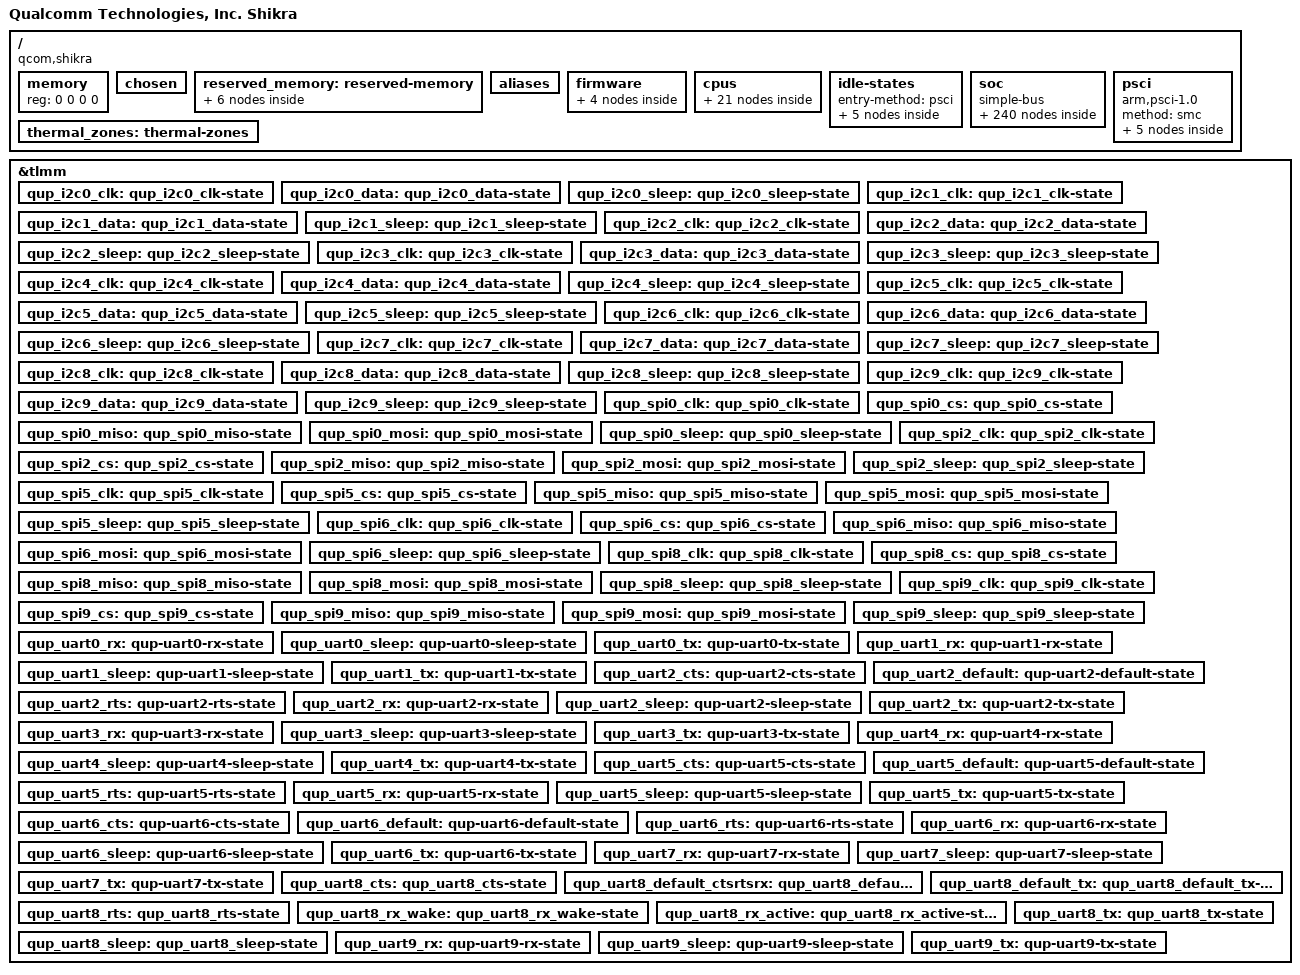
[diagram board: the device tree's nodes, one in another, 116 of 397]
// SPDX-License-Identifier: BSD-3-Clause
/*
 * Copyright (c) Qualcomm Technologies, Inc. and/or its subsidiaries.
 */

#include <dt-bindings/arm/msm/qti-smmu-proxy-dt-ids.h>
#include <dt-bindings/clock/qcom,rpmcc.h>
#include <dt-bindings/clock/qcom,shikra-audiocorecc.h>
#include <dt-bindings/clock/qcom,shikra-dispcc.h>
#include <dt-bindings/clock/qcom,shikra-gcc.h>
#include <dt-bindings/clock/qcom,shikra-gpucc.h>
#include <dt-bindings/dma/qcom-gpi.h>
#include <dt-bindings/interconnect/qcom,shikra.h>
#include <dt-bindings/interconnect/qcom,icc.h>
#include <dt-bindings/interrupt-controller/arm-gic.h>
#include <dt-bindings/regulator/qcom,rpm-smd-regulator.h>

/ {
	model = "Qualcomm Technologies, Inc. Shikra";
	compatible = "qcom,shikra";
	qcom,msm-id = <756 0x10000 >;
	interrupt-parent = <&intc>;
	#address-cells = <2>;
	#size-cells = <2>;
	memory { device_type = "memory"; reg = <0 0 0 0>; };

	chosen: chosen {
		bootargs = "android_arch_task_struct_size=512 pcie_ports=compat kasan=off irqaffinity=0-1 cpufreq.default_governor=performance printk.console_no_auto_verbose=1 rcupdate.rcu_expedited=1 rcu_nocbs=0-4 cgroup_disable=pressure cgroup.memory=nokmem,nosocket page_poison=on restrict_cma_redirect=false nokaslr kpti=0 log_buf_len=256K swiotlb=0 loop.max_part=7 loglevel=8 bootconfig sysctl.kernel.sched_pelt_multiplier=4 no-steal-acc fw_devlink.strict=1";

	};

	reserved_memory: reserved-memory { };

	aliases: aliases {
		serial0 = &uart0;
		mmc0 = &sdhc_1;
		mmc1 = &sdhc_2; /* SDC2 SD card slot */
		i2c3 = &i2c3;
		hsuart0 = &uart8;
	};

	firmware: firmware {
		qcom_scm: qcom_scm { };
	};

	cpus {
		#address-cells = <2>;
		#size-cells = <0>;

		CPU0: cpu@0 {
			device_type = "cpu";
			compatible = "qcom,kryo";
			reg = <0x0 0x0>;
			enable-method = "psci";
			cpu-idle-states = <&SILVER_OFF &SILVER_RAIL_OFF>;
			power-domains = <&CPU_PD0>;
			power-domain-names = "psci";
			d-cache-size = <0x8000>;
			i-cache-size = <0x8000>;
			next-level-cache = <&L3_0>;
			qcom,freq-domain = <&cpufreq_hw 0>;
			capacity-dmips-mhz = <1024>;
			dynamic-power-coefficient = <100>;
			#cooling-cells = <2>;

			L1_I_0: l1-icache {
				compatible = "cache";
			};

			L1_D_0: l1-dcache {
				compatible = "cache";
			};

			L3_0: l3-cache {
				compatible = "cache";
				cache-level = <3>;
				cache-size = <0x80000>;
			};
		};

		CPU1: cpu@100 {
			device_type = "cpu";
			compatible = "qcom,kryo";
			reg = <0x0 0x100>;
			enable-method = "psci";
			cpu-idle-states = <&SILVER_OFF &SILVER_RAIL_OFF>;
			power-domains = <&CPU_PD1>;
			power-domain-names = "psci";
			d-cache-size = <0x8000>;
			i-cache-size = <0x8000>;
			next-level-cache = <&L3_0>;
			qcom,freq-domain = <&cpufreq_hw 0>;
			capacity-dmips-mhz = <1024>;
			dynamic-power-coefficient = <100>;
			#cooling-cells = <2>;

			L1_I_1: l1-icache {
				compatible = "cache";
			};

			L1_D_1: l1-dcache {
				compatible = "cache";
			};
		};

		CPU2: cpu@200 {
			device_type = "cpu";
			compatible = "qcom,kryo";
			reg = <0x0 0x200>;
			enable-method = "psci";
			cpu-idle-states = <&SILVER_OFF &SILVER_RAIL_OFF>;
			power-domains = <&CPU_PD2>;
			power-domain-names = "psci";
			d-cache-size = <0x8000>;
			i-cache-size = <0x8000>;
			next-level-cache = <&L3_0>;
			qcom,freq-domain = <&cpufreq_hw 0>;
			capacity-dmips-mhz = <1024>;
			dynamic-power-coefficient = <100>;
			#cooling-cells = <2>;

			L1_I_2: l1-icache {
				compatible = "cache";
			};

			L1_D_2: l1-dcache {
				compatible = "cache";
			};
		};

		CPU3: cpu@300 {
			device_type = "cpu";
			compatible = "qcom,kryo";
			reg = <0x0 0x300>;
			enable-method = "psci";
			cpu-idle-states = <&GOLD_OFF &GOLD_RAIL_OFF>;
			power-domains = <&CPU_PD3>;
			power-domain-names = "psci";
			d-cache-size = <0x8000>;
			i-cache-size = <0x8000>;
			next-level-cache = <&L2_3>;
			qcom,freq-domain = <&cpufreq_hw 1>;
			capacity-dmips-mhz = <2273>;
			dynamic-power-coefficient = <494>;
			#cooling-cells = <2>;

			L1_I_3: l1-icache {
				compatible = "cache";
			};

			L1_D_3: l1-dcache {
				compatible = "cache";
			};

			L2_3: l2-cache {
				compatible = "cache";
				cache-level = <2>;
				cache-size = <0x40000>;
				next-level-cache = <&L3_0>;
			};
		};

		cpu-map {
			cluster0 {
				core0 {
					cpu = <&CPU0>;
				};

				core1 {
					cpu = <&CPU1>;
				};

				core2 {
					cpu = <&CPU2>;
				};
			};

			cluster1 {
				core0 {
					cpu = <&CPU3>;
				};
			};
		};
	};

	idle-states {
		entry-method = "psci";

		SILVER_OFF: silver-c3 {  /* C3 */
			compatible = "arm,idle-state";
			idle-state-name = "pc";
			entry-latency-us = <549>;
			exit-latency-us = <901>;
			min-residency-us = <1774>;
			arm,psci-suspend-param = <0x40000003>;
			local-timer-stop;
		};

		SILVER_RAIL_OFF: silver-cluster0-c4 { /* C4 */
			compatible = "arm,idle-state";
			idle-state-name = "rail-pc";
			entry-latency-us = <702>;
			exit-latency-us = <915>;
			min-residency-us = <4001>;
			arm,psci-suspend-param = <0x40000004>;
			local-timer-stop;
		};

		GOLD_OFF: gold-c3 {  /* C3 */
			compatible = "arm,idle-state";
			idle-state-name = "pc";
			entry-latency-us = <523>;
			exit-latency-us = <1244>;
			min-residency-us = <2207>;
			arm,psci-suspend-param = <0x40000003>;
			local-timer-stop;
		};

		GOLD_RAIL_OFF: gold-cluster1-c4 { /* C4 */
			compatible = "arm,idle-state";
			idle-state-name = "rail-pc";
			entry-latency-us = <526>;
			exit-latency-us = <1854>;
			min-residency-us = <5555>;
			arm,psci-suspend-param = <0x40000004>;
			local-timer-stop;
		};

		CLUSTER_PWR_DN: cluster-d4 { /* D4 */
			compatible = "domain-idle-state";
			idle-state-name = "l3-pc";
			entry-latency-us = <2752>;
			exit-latency-us = <3038>;
			min-residency-us = <6118>;
			arm,psci-suspend-param = <0x41000044>;
		};
	};

	soc: soc { };

	thermal_zones: thermal-zones {};

	psci {
		compatible = "arm,psci-1.0";
		method = "smc";

		CPU_PD0: cpu-pd0 {
			#power-domain-cells = <0>;
			power-domains = <&CLUSTER_PD>;
		};

		CPU_PD1: cpu-pd1 {
			#power-domain-cells = <0>;
			power-domains = <&CLUSTER_PD>;
		};

		CPU_PD2: cpu-pd2 {
			#power-domain-cells = <0>;
			power-domains = <&CLUSTER_PD>;
		};

		CPU_PD3: cpu-pd3 {
			#power-domain-cells = <0>;
			power-domains = <&CLUSTER_PD>;
		};

		CLUSTER_PD: cluster-pd {
			#power-domain-cells = <0>;
			domain-idle-states = <&CLUSTER_PWR_DN>;
		};
	};
};

&firmware {
	qcom_scm {
		compatible = "qcom,scm";
		qcom,dload-mode = <&tcsr 0x13000>;
	};

	qcom_smcinvoke {
		compatible = "qcom,smcinvoke";
	};

	qcom_mem_object {
		compatible = "qcom,mem-object";
	};

	qtee_shmbridge {
		compatible = "qcom,tee-shared-memory-bridge";
	};
};

&soc {
	#address-cells = <1>;
	#size-cells = <1>;
	ranges = <0 0 0 0xffffffff>;
	compatible = "simple-bus";

	rpm_bus: qcom,rpm-smd {
		compatible = "qcom,rpm-smd";
		rpm-channel-name = "rpm_requests";
		interrupts = <GIC_SPI 194 IRQ_TYPE_EDGE_RISING>;
		rpm-channel-type = <15>; /* SMD_APPS_RPM */
		power-domains = <&CLUSTER_PD>;
	};

	cluster-device {
		compatible = "qcom,lpm-cluster-dev";
		power-domains = <&CLUSTER_PD>;
	};

	mpm: interrupt-controller@45f01b8 {
		compatible = "qcom,mpm-shikra", "qcom,mpm";
		reg = <0x045f01b8 0x1000>,
		      <0x0f40000c 0x4>,  /* MSM_APCS_GCC_BASE 4K */
		      <0x0f421000 0x1000>;
		reg-names = "vmpm", "ipc", "timer";
		interrupts = <GIC_SPI 197 IRQ_TYPE_EDGE_RISING>;
		qcom,num-mpm-irqs = <96>;
		interrupt-controller;
		interrupt-parent = <&intc>;
		#interrupt-cells = <2>;
	};

	msm_gpu: qcom,kgsl-3d0@5900000 { };

	intc: interrupt-controller@f200000 {
		compatible = "arm,gic-v3";
		#interrupt-cells = <3>;
		interrupt-controller;
		#redistributor-regions = <1>;
		redistributor-stride = <0x0 0x20000>;
		reg = <0xf200000 0x10000>,	/* GICD */
		      <0xf240000 0x80000>;	/* GICR * 4 */
		interrupts = <GIC_PPI 8 IRQ_TYPE_LEVEL_HIGH>;
	};

	qcom_tzlog: tz-log@c11e720 {
		compatible = "qcom,tz-log";
		reg = <0xc11e720 0x3000>;
		qcom,hyplog-enabled;
		hyplog-address-offset = <0x410>;
		hyplog-size-offset = <0x414>;
	};

	arch_timer: timer {
		compatible = "arm,armv8-timer";
		interrupts = <GIC_PPI 1 (GIC_CPU_MASK_SIMPLE(8) | IRQ_TYPE_LEVEL_LOW)>,
			     <GIC_PPI 2 (GIC_CPU_MASK_SIMPLE(8) | IRQ_TYPE_LEVEL_LOW)>,
			     <GIC_PPI 3 (GIC_CPU_MASK_SIMPLE(8) | IRQ_TYPE_LEVEL_LOW)>,
			     <GIC_PPI 0 (GIC_CPU_MASK_SIMPLE(8) | IRQ_TYPE_LEVEL_LOW)>;
		clock-frequency = <19200000>;
	};
	ethernet: ethernet@5d00000 {
		compatible = "qcom,shikra-ethqos";
		reg = <0x05d00000 0x10000>,
		      <0x05d16000 0x100>;
		reg-names = "stmmaceth", "rgmii";

		clocks = <&gcc GCC_EMAC0_AXI_CLK>,
			 <&gcc GCC_EMAC0_AHB_CLK>,
			 <&gcc GCC_EMAC0_PTP_CLK>,
			 <&gcc GCC_EMAC0_RGMII_CLK>,
			 <&gcc GCC_EMAC0_AXI_CLK>,
			 <&gcc GCC_EMAC0_AXI_SYS_NOC_CLK>,
			 <&gcc GCC_PCIE_TILE_AXI_SYS_NOC_CLK>;
		clock-names = "stmmaceth", "pclk", "ptp_ref", "rgmii",
			      "axi", "axi-noc", "pcie-tile-axi-noc";

		interrupts = <GIC_SPI 478 IRQ_TYPE_LEVEL_HIGH>,
			     <GIC_SPI 469 IRQ_TYPE_LEVEL_HIGH>;
		interrupt-names = "macirq", "eth_lpi";

		power-domains = <&gcc GCC_EMAC0_GDSC>;
		resets = <&gcc GCC_EMAC0_BCR>;
		reset-names = "stmmaceth";
		iommus = <&apps_smmu 0x380 0x7>;
		qcom,iommu-dma = "atomic";

		interconnect-names = "axi_icc_path", "apb_icc_path";
		interconnects = <&system_noc MASTER_EMAC_0 &mc_virt SLAVE_EBI_CH0>,
				<&mem_noc MASTER_AMPSS_M0 &config_noc SLAVE_EMAC0_CFG>;

		snps,tso;
		snps,pbl = <32>;
		rx-fifo-depth = <8192>;
		tx-fifo-depth = <8192>;

		status = "disabled";
	};

	memtimer: timer@f420000 {
		#address-cells = <1>;
		#size-cells = <1>;
		ranges;
		compatible = "arm,armv7-timer-mem";
		reg = <0x0f420000 0x1000>;
		clock-frequency = <19200000>;

		frame@f421000 {
			frame-number = <0>;
			interrupts = <GIC_SPI 8 IRQ_TYPE_LEVEL_HIGH>,
				     <GIC_SPI 6 IRQ_TYPE_LEVEL_HIGH>;
			reg = <0x0f421000 0x1000>,
			      <0x0f422000 0x1000>;
		};

		frame@f423000 {
			frame-number = <1>;
			interrupts = <GIC_SPI 9 IRQ_TYPE_LEVEL_HIGH>;
			reg = <0xf243000 0x1000>;
			status = "disabled";
		};

		frame@f425000 {
			frame-number = <2>;
			interrupts = <GIC_SPI 10 IRQ_TYPE_LEVEL_HIGH>;
			reg = <0xf425000 0x1000>;
			status = "disabled";
		};

		frame@f427000 {
			frame-number = <3>;
			interrupts = <GIC_SPI 11 IRQ_TYPE_LEVEL_HIGH>;
			reg = <0xf427000 0x1000>;
			status = "disabled";
		};

		frame@f429000 {
			frame-number = <4>;
			interrupts = <GIC_SPI 12 IRQ_TYPE_LEVEL_HIGH>;
			reg = <0xf429000 0x1000>;
			status = "disabled";
		};

		frame@f42b000 {
			frame-number = <5>;
			interrupts = <GIC_SPI 13 IRQ_TYPE_LEVEL_HIGH>;
			reg = <0xf42b000 0x1000>;
			status = "disabled";
		};

		frame@f42d000 {
			frame-number = <6>;
			interrupts = <GIC_SPI 14 IRQ_TYPE_LEVEL_HIGH>;
			reg = <0xf42d000 0x1000>;
			status = "disabled";
		};
	};

	wdog: qcom,wdt@f410000 {
		compatible = "qcom,msm-watchdog";
		reg = <0xf410000 0x1000>;
		reg-names = "wdt-base";
		interrupts = <GIC_SPI 0 IRQ_TYPE_LEVEL_HIGH>,
			     <GIC_SPI 1 IRQ_TYPE_LEVEL_HIGH>;
		qcom,bark-time = <11000>;
		qcom,pet-time = <9360>;
		qcom,ipi-ping;
		qcom,wakeup-enable;
		status = "ok";
	};

	gic-interrupt-router {
		compatible = "qcom,gic-intr-routing";
		/* keep a few m cores in class0 only to avoid wakeup of l cores */
		qcom,gic-class0-cpus = <&CPU0 &CPU1 &CPU2>;
		/* keep other cores in class1 */
		qcom,gic-class1-cpus = <&CPU3>;
	};

	qcom,mem-buf {
		compatible = "qcom,mem-buf";
		qcom,mem-buf-capabilities = "supplier";
		qcom,vmid = <3>;
	};

	qcom,mem-buf-msgq {
		compatible = "qcom,mem-buf-msgq";
		qcom,msgq-names = "trusted_vm", "oem_vm";
	};

	qcom,test-large-dmabuf-tuivm {
		compatible = "qcom,gh-large-dmabuf-test";
		gunyah-label = <0x10d>;
		qcom,primary;
	};

	kryo-erp {
		compatible = "arm,arm64-kryo-cpu-erp";
		interrupts = <GIC_PPI 6 IRQ_TYPE_LEVEL_HIGH>,
			     <GIC_SPI 35 IRQ_TYPE_LEVEL_HIGH>;
		interrupt-names = "l1-l2-faultirq","l3-scu-faultirq";
	};

	qcom,rmtfs_sharedmem@0 {
		compatible = "qcom,sharedmem-uio";
		reg = <0x0 0x400000>;
		reg-names = "rmtfs";
		qcom,client-id = <0x00000001>;
		qcom,guard-memory;
		qcom,vm-nav-path;
	};

	cpu_pmu: cpu-pmu {
		compatible = "arm,armv8-pmuv3";
		interrupts = <GIC_PPI 5 IRQ_TYPE_LEVEL_HIGH>;
	};

	clocks {
		xo_board: xo_board {
			compatible = "fixed-clock";
			clock-frequency = <38400000>;
			clock-output-names = "xo_board";
			#clock-cells = <0>;
		};

		sleep_clk: sleep_clk {
			compatible = "fixed-clock";
			clock-frequency = <32764>;
			clock-output-names = "sleep_clk";
			#clock-cells = <0>;
		};

		emac0_sgmiiphy_rclk: emac0_sgmiiphy_rclk {
			compatible = "fixed-clock";
			clock-frequency = <1000>;
			clock-output-names = "emac0_sgmiiphy_rclk";
			#clock-cells = <0>;
		};

		emac0_sgmiiphy_tclk: emac0_sgmiiphy_tclk {
			compatible = "fixed-clock";
			clock-frequency = <1000>;
			clock-output-names = "emac0_sgmiiphy_tclk";
			#clock-cells = <0>;
		};

		emac1_sgmiiphy_rclk: emac1_sgmiiphy_rclk {
			compatible = "fixed-clock";
			clock-frequency = <1000>;
			clock-output-names = "emac1_sgmiiphy_rclk";
			#clock-cells = <0>;
		};

		emac1_sgmiiphy_tclk: emac1_sgmiiphy_tclk {
			compatible = "fixed-clock";
			clock-frequency = <1000>;
			clock-output-names = "emac1_sgmiiphy_tclk";
			#clock-cells = <0>;
		};

		pcie_pipe_clk: pcie_pipe_clk {
			compatible = "fixed-clock";
			clock-frequency = <1000>;
			clock-output-names = "pcie_pipe_clk";
			#clock-cells = <0>;
		};

		usb3_phy_wrapper_gcc_usb30_pipe_clk: usb3_phy_wrapper_gcc_usb30_pipe_clk {
			compatible = "fixed-clock";
			clock-frequency = <1000>;
			clock-output-names = "usb3_phy_wrapper_gcc_usb30_pipe_clk";
			#clock-cells = <0>;
		};
	};

	rpmcc: clock-controller {
		compatible = "qcom,rpmcc-shikra";
		#clock-cells = <1>;
	};

	audiocorecc: clock-controller@a0a0000 {
		compatible = "qcom,shikra-audiocorecc";
		reg = <0xa0a0000 0x10000>;
		reg-name = "cc_base";
		vdd_cx-supply = <&VDD_CX_LEVEL>;
		clocks = <&rpmcc RPM_SMD_XO_CLK_SRC>,
			 <&gcc GCC_LPASS_CONFIG_CLK>,
			 <&gcc GCC_LPASS_CORE_AXIM_CLK>,
			 <&sleep_clk>;
		clock-names = "bi_tcxo",
			      "lpass_config_clk",
			      "lpass_core_axim_clk",
			      "sleep_clk";
		#clock-cells = <1>;
		#reset-cells = <1>;
		status = "disabled";
	};

	dispcc: clock-controller@5f00000 {
		compatible = "qcom,shikra-dispcc", "syscon";
		reg = <0x5f00000 0x20000>;
		reg-name = "cc_base";
		vdd_cx-supply = <&VDD_CX_LEVEL>;
		clocks = <&rpmcc RPM_SMD_XO_CLK_SRC>,
			 <&sleep_clk>,
			 <&gcc GCC_DISP_AHB_CLK>,
			 <&gcc GCC_DISP_GPLL0_DIV_CLK_SRC>;
		clock-names = "bi_tcxo",
			      "sleep_clk",
			      "iface",
			      "gcc_disp_gpll0_div_clk_src";
		#clock-cells = <1>;
		#reset-cells = <1>;
		#power-domain-cells = <1>;
	};

	gcc: clock-controller@1400000 {
		compatible = "qcom,shikra-gcc", "syscon";
		reg = <0x1400000 0x1f0000>;
		reg-name = "cc_base";
		vdd_cx-supply = <&VDD_CX_LEVEL>;
		vdd_mx-supply = <&VDD_MX_LEVEL>;
		clocks = <&rpmcc RPM_SMD_XO_CLK_SRC>,
			 <&emac0_sgmiiphy_rclk>,
			 <&emac0_sgmiiphy_tclk>,
			 <&emac1_sgmiiphy_rclk>,
			 <&emac1_sgmiiphy_tclk>,
			 <&pcie_pipe_clk>,
			 <&sleep_clk>,
			 <&usb3_phy_wrapper_gcc_usb30_pipe_clk>;
		clock-names = "bi_tcxo",
			      "emac0_sgmiiphy_rclk",
			      "emac0_sgmiiphy_tclk",
			      "emac1_sgmiiphy_rclk",
			      "emac1_sgmiiphy_tclk",
			      "pcie_pipe_clk",
			      "sleep_clk",
			      "usb3_phy_wrapper_gcc_usb30_pipe_clk";
		protected-clocks = <GCC_LPASS_CONFIG_CLK>,
				   <GCC_LPASS_CORE_AXIM_CLK>;
		#clock-cells = <1>;
		#reset-cells = <1>;
		#power-domain-cells = <1>;
	};

	gpucc: clock-controller@5990000 {
		compatible = "qcom,shikra-gpucc", "syscon";
		reg = <0x5990000 0x9000>;
		reg-name = "cc_base";
		vdd_cx-supply = <&VDD_CX_LEVEL>;
		clocks = <&rpmcc RPM_SMD_XO_CLK_SRC>,
			 <&gcc GCC_GPU_GPLL0_CLK_SRC>,
			 <&gcc GCC_GPU_GPLL0_DIV_CLK_SRC>;
		clock-names = "bi_tcxo",
			      "gpll0_out_main",
			      "gpll0_out_main_div";
		#clock-cells = <1>;
		#reset-cells = <1>;
		#power-domain-cells = <1>;
	};

	cpufreq_hw: qcom,cpufreq-hw {
		compatible = "qcom,cpufreq-rimps";
		reg = <0xfd91000 0x1000>,
		      <0xfd92000 0x1000>;
		reg-names = "freq-domain0",
			    "freq-domain1";
		clocks = <&rpmcc RPM_SMD_XO_CLK_SRC>, <&gcc GPLL0>;
		clock-names = "xo", "alternate";
		interrupts = <GIC_SPI 30 IRQ_TYPE_LEVEL_HIGH>,
			     <GIC_SPI 31 IRQ_TYPE_LEVEL_HIGH>;
		interrupt-names = "dcvsh0_int",
				  "dcvsh1_int";
		#freq-domain-cells = <1>;
	};

	qcom,cpufreq-hw-debug {
		compatible = "qcom,cpufreq-hw-epss-debug";
		qcom,freq-hw-domain = <&cpufreq_hw 0>,
				      <&cpufreq_hw 1>;
	};

	mccc_debug: syscon@cba000 {
		compatible = "syscon";
		reg = <0xcba000 0x54>;
	};

	cpucc_debug: syscon@faa0018 {
		compatible = "syscon";
		reg = <0xfaa0018 0x4>;
	};

	debugcc: clock-controller@0 {
		compatible = "qcom,shikra-debugcc";
		qcom,gcc = <&gcc>;
		qcom,dispcc = <&dispcc>;
		qcom,gpucc = <&gpucc>;
		qcom,mccc = <&mccc_debug>;
		qcom,cpucc = <&cpucc_debug>;
		clocks = <&rpmcc RPM_SMD_XO_CLK_SRC>,
			 <&gcc 0>,
			 <&dispcc 0>,
			 <&gpucc 0>;
		clock-names = "xo_clk_src",
			      "gcc",
			      "dispcc",
			      "gpucc";
		#clock-cells = <1>;
	};

	clk_virt: interconnect@0 {
		compatible = "qcom,shikra-clk_virt";
		#interconnect-cells = <1>;
		qcom,keepalive;
		clock-names = "bus", "bus_a";
		clocks = <&rpmcc RPM_SMD_QUP_CLK>,
			 <&rpmcc RPM_SMD_QUP_A_CLK>;
	};

	mc_virt: interconnect@1 {
		reg = <0x04480000 0x80000>;
		compatible = "qcom,shikra-mc_virt";
		#interconnect-cells = <1>;
		qcom,util-factor = <152>;
		qcom,keepalive;
		clock-names = "bus", "bus_a";
		clocks = <&rpmcc RPM_SMD_BIMC_CLK>,
			 <&rpmcc RPM_SMD_BIMC_A_CLK>;
	};

	mem_noc: interconnect@d00000 {
		reg = <0x00d00000 0x43080>;
		compatible = "qcom,shikra-mem_noc_core";
		#interconnect-cells = <1>;
		qcom,util-factor = <142>;
		qcom,keepalive;
		clock-names = "bus", "bus_a";
		clocks = <&rpmcc RPM_SMD_CPUSS_GNOC_CLK>,
			 <&rpmcc RPM_SMD_CPUSS_GNOC_A_CLK>,
			 <&gcc GCC_DDRSS_GPU_AXI_CLK>;
	};

	mmnrt_virt: interconnect1@1880000 {
		reg = <0x01880000 0x6a080>;
		compatible = "qcom,shikra-mmnrt_virt";
		#interconnect-cells = <1>;
		qcom,util-factor = <142>;
		qcom,keepalive;
		clock-names = "bus", "bus_a";
		clocks = <&rpmcc RPM_SMD_MMNRT_CLK>,
			 <&rpmcc RPM_SMD_MMNRT_A_CLK>;
	};

	mmrt_virt: interconnect2@1880000 {
		reg = <0x01880000 0x6a080>;
		compatible = "qcom,shikra-mmrt_virt";
		#interconnect-cells = <1>;
		qcom,util-factor = <142>;
		qcom,keepalive;
		clock-names = "bus", "bus_a";
		clocks = <&rpmcc RPM_SMD_MMRT_CLK>,
			 <&rpmcc RPM_SMD_MMRT_A_CLK>;
	};

	system_noc: interconnect@1880000 {
		reg = <0x01880000 0x6a080>;
		compatible = "qcom,shikra-sys_noc";
		#interconnect-cells = <1>;
		qcom,keepalive;
		clock-names = "bus", "bus_a";
		clocks = <&rpmcc RPM_SMD_SNOC_CLK>,
			 <&rpmcc RPM_SMD_SNOC_A_CLK>,
			 <&gcc GCC_EMAC0_AXI_SYS_NOC_CLK>,
			 <&gcc GCC_EMAC1_AXI_SYS_NOC_CLK>,
			 <&gcc GCC_SYS_NOC_USB2_PRIM_AXI_CLK>,
			 <&gcc GCC_SYS_NOC_USB3_PRIM_AXI_CLK>;
	};

	config_noc: interconnect@1900000 {
		reg = <0x01900000 0x8080>;
		compatible = "qcom,shikra-config_noc";
		#interconnect-cells = <1>;
		qcom,keepalive;
		clock-names = "bus", "bus_a";
		clocks = <&rpmcc RPM_SMD_CNOC_CLK>,
			 <&rpmcc RPM_SMD_CNOC_A_CLK>;
	};

	vendor_hooks: qcom,cpu-vendor-hooks {
		compatible = "qcom,cpu-vendor-hooks";
	};

	qcom,secure-buffer {
		compatible = "qcom,secure-buffer";
		qcom,vmid-cp-camera-preview-ro;
	};

	qti,smmu-proxy {
		compatible = "smmu-proxy-sender";
	};

	qcom,seccamtest {
		compatible = "qcom,seccamtest";
		qti,smmu-proxy-cb-id = <QTI_SMMU_PROXY_CAMERA_CB>;
	};

	logbuf: qcom,logbuf-vendor-hooks {
		compatible = "qcom,logbuf-vendor-hooks";
	};

	va_mini_dump {
		compatible = "qcom,va-minidump";
		memory-region = <&va_md_mem>;
		status = "ok";
	};

	google,debug-kinfo {
		compatible = "google,debug-kinfo";
		memory-region = <&kinfo_mem>;
	};

	mini_dump_mode {
		compatible = "qcom,minidump";
		status = "ok";
	};

	qcom,mpm2-sleep-counter@4403000 {
		compatible = "qcom,mpm2-sleep-counter";
		reg = <0x4403000 0x1000>;
		clock-frequency = <32768>;
	};

	tcsr_mutex_block: syscon@340000 {
		compatible = "syscon";
		reg = <0x340000 0x20000>;
	};

	tcsr_mutex: hwlock {
		compatible = "qcom,tcsr-mutex";
		syscon = <&tcsr_mutex_block 0 0x1000>;
		#hwlock-cells = <1>;
	};

	rpm_msg_ram: memory@45f0000 {
		compatible = "qcom,rpm-msg-ram";
		reg = <0x45f0000 0x7000>;
	};

	sram@4690000 {
		compatible = "qcom,rpm-stats-v2";
		reg = <0x04690000 0x10000>;
		ss-name = "modem", "cdsp", "apss", "lmcu";
	};

	apcs_glb: mailbox@f400000 {
		compatible = "qcom,shikra-apcs-hmss-global";
		reg = <0xf400000 0x1000>;
		#mbox-cells = <1>;
	};

	rpm-glink {
		compatible = "qcom,glink-rpm";
		interrupts = <GIC_SPI 194 IRQ_TYPE_EDGE_RISING>;
		qcom,rpm-msg-ram = <&rpm_msg_ram>;
		mboxes = <&apcs_glb 0>;
	};

	qcom,smp2p-modem {
		compatible = "qcom,smp2p";
		qcom,smem = <435>, <428>;
		interrupts = <GIC_SPI 70 IRQ_TYPE_EDGE_RISING>;
		mboxes = <&apcs_glb 14>;
		qcom,local-pid = <0>;
		qcom,remote-pid = <1>;

		modem_smp2p_out: master-kernel {
			qcom,entry-name = "master-kernel";
			#qcom,smem-state-cells = <1>;
		};

		modem_smp2p_in: slave-kernel {
			qcom,entry-name = "slave-kernel";
			interrupt-controller;
			#interrupt-cells = <2>;
		};

		smp2p_ipa_1_out: qcom,smp2p-ipa-1-out {
			qcom,entry-name = "ipa";
			#qcom,smem-state-cells = <1>;
		};

		/* ipa - inbound entry from mss */
		smp2p_ipa_1_in: qcom,smp2p-ipa-1-in {
			qcom,entry-name = "ipa";
			interrupt-controller;
			#interrupt-cells = <2>;
		};

		smp2p_wlan_1_in: qcom,smp2p-wlan-1-in {
			qcom,entry-name = "wlan";
			interrupt-controller;
			#interrupt-cells = <2>;
		};

	};

	qcom,smp2p-cdsp {
		compatible = "qcom,smp2p";
		qcom,smem = <94>, <432>;
		interrupts = <GIC_SPI 263 IRQ_TYPE_EDGE_RISING>;
		mboxes = <&apcs_glb 6>;
		qcom,local-pid = <0>;
		qcom,remote-pid = <5>;

		cdsp_smp2p_out: master-kernel {
			qcom,entry-name = "master-kernel";
			#qcom,smem-state-cells = <1>;
		};

		cdsp_smp2p_in: slave-kernel {
			qcom,entry-name = "slave-kernel";
			interrupt-controller;
			#interrupt-cells = <2>;
		};

		smp2p_rdbg5_out: qcom,smp2p-rdbg5-out {
			qcom,entry-name = "rdbg";
			#qcom,smem-state-cells = <1>;
		};

		smp2p_rdbg5_in: qcom,smp2p-rdbg5-in {
			qcom,entry-name = "rdbg";
			interrupt-controller;
			#interrupt-cells = <2>;
		};
	};

	qcom,smp2p-lmcu {
		compatible = "qcom,smp2p";
		qcom,smem = <617>, <616>;
		interrupts = <GIC_SPI 287 IRQ_TYPE_EDGE_RISING>;
		mboxes = <&apcs_glb 10>;
		qcom,local-pid = <0>;
		qcom,remote-pid = <26>;

		lmcu_smp2p_out: master-kernel {
			qcom,entry-name = "master-kernel";
			#qcom,smem-state-cells = <1>;
		};

		lmcu_smp2p_in: slave-kernel {
			qcom,entry-name = "slave-kernel";
			interrupt-controller;
			#interrupt-cells = <2>;
		};

		lmcu_sleepstate_smp2p_out: sleepstate-out {
			qcom,entry-name = "sleepstate";
			#qcom,smem-state-cells = <1>;
		};

		lmcu_sleepstate_smp2p_in: qcom,sleepstate-in {
			qcom,entry-name = "sleepstate_see";
			interrupt-controller;
			#interrupt-cells = <2>;
		};
	};

	qcom,smp2p_sleepstate_lmcu {
		compatible = "qcom,smp2p-sleepstate";
		qcom,smem-states = <&lmcu_sleepstate_smp2p_out 0>;
		interrupt-parent = <&lmcu_sleepstate_smp2p_in>;
		interrupts = <0 0>;
		label = "lmcu";
		interrupt-names = "smp2p-sleepstate-in";
	};

	apcs: syscon@f400000 {
		compatible = "syscon";
		reg = <0xf400000 0x1000>;
	};

	qcom,smsm {
		compatible = "qcom,smsm";

		#address-cells = <1>;
		#size-cells = <0>;

		qcom,ipc-1 = <&apcs 12 13>;

		apps_smsm_out: apps@0 {
			reg = <0>;
			#qcom,smem-state-cells = <1>;
		};

		modem_smsm_in: modem@1 {
			reg = <1>;
			interrupts = <GIC_SPI 69 IRQ_TYPE_EDGE_RISING>;

			interrupt-controller;
			#interrupt-cells = <2>;
		};
	};

	qcom,bam_dmux@6044000 {
		compatible = "qcom,bam_dmux";
		reg = <0x6044000 0x19000>;
		qcom,rx-ring-size = <32>;
		qcom,max-rx-mtu = <4096>;
		qcom,fast-shutdown;
		qcom,smem-states = <&apps_smsm_out 1>, <&apps_smsm_out 11>;
		qcom,smem-state-names = "pwrctrl", "pwrctrlack";
		interrupts-extended =
			<&intc GIC_SPI 74 IRQ_TYPE_EDGE_RISING>,
			<&modem_smsm_in 1 IRQ_TYPE_EDGE_BOTH>,
			<&modem_smsm_in 11 IRQ_TYPE_EDGE_BOTH>;
		interrupt-names = "dmux", "ctrl", "ack";
		};

	qup0_gpi_iommu_region: qup0_gpi_iommu_region {
		iommu-addresses = <&gpi_dma0 0x0 0x100000>,
				  <&gpi_dma0 0x200000 0xffe00000>;
	};

	gpi_dma0: qcom,gpi-dma@4a00000 {
		compatible = "qcom,gpi-dma";
		#dma-cells = <5>;
		reg = <0x4a00000 0x60000>;
		reg-names = "gpi-top";
		iommus = <&apps_smmu 0xf6 0x0>;
		qcom,max-num-gpii = <16>;
		interrupts = <GIC_SPI 511 IRQ_TYPE_LEVEL_HIGH>,
			     <GIC_SPI 512 IRQ_TYPE_LEVEL_HIGH>,
			     <GIC_SPI 513 IRQ_TYPE_LEVEL_HIGH>,
			     <GIC_SPI 514 IRQ_TYPE_LEVEL_HIGH>,
			     <GIC_SPI 515 IRQ_TYPE_LEVEL_HIGH>,
			     <GIC_SPI 516 IRQ_TYPE_LEVEL_HIGH>,
			     <GIC_SPI 517 IRQ_TYPE_LEVEL_HIGH>,
			     <GIC_SPI 518 IRQ_TYPE_LEVEL_HIGH>,
			     <GIC_SPI 519 IRQ_TYPE_LEVEL_HIGH>,
			     <GIC_SPI 520 IRQ_TYPE_LEVEL_HIGH>,
			     <GIC_SPI 521 IRQ_TYPE_LEVEL_HIGH>,
			     <GIC_SPI 522 IRQ_TYPE_LEVEL_HIGH>,
			     <GIC_SPI 523 IRQ_TYPE_LEVEL_HIGH>,
			     <GIC_SPI 524 IRQ_TYPE_LEVEL_HIGH>,
			     <GIC_SPI 525 IRQ_TYPE_LEVEL_HIGH>,
			     <GIC_SPI 526 IRQ_TYPE_LEVEL_HIGH>;
		qcom,static-gpii-mask = <0x1>;
		qcom,gpii-mask = <0xfe>;
		qcom,ev-factor = <1>;
		memory-region = <&qup0_gpi_iommu_region>;
		qcom,gpi-ee-offset = <0x10000>;
		status = "disabled";
	};

	qup0_se_iommu_region: qup0_se_iommu_region {
		iommu-addresses = <&qupv3_id_0 0x0 0x40000000>,
				  <&qupv3_id_0 0x50000000 0xb0000000>;
	};

	qupv3_id_0: geniqup@4ac0000 {
		compatible = "qcom,geni-se-qup";
		reg = <0x4ac0000 0x2000>;
		clocks = <&gcc GCC_QUPV3_WRAP_0_M_AHB_CLK>,
			 <&gcc GCC_QUPV3_WRAP_0_S_AHB_CLK>;
		clock-names = "m-ahb",
			      "s-ahb";
		ranges;
		iommus = <&apps_smmu 0xe3 0x0>;
		memory-region = <&qup0_se_iommu_region>;
		qcom,iommu-geometry = <0x40000000 0x10000000>;
		qcom,iommu-dma = "fastmap";
		#address-cells = <1>;
		#size-cells = <1>;
		status = "disabled";

		i2c0: i2c@4a80000 {
			compatible = "qcom,i2c-geni";
			reg = <0x4a80000 0x4000>;
			interrupts = <GIC_SPI 527 IRQ_TYPE_LEVEL_HIGH>;
			clocks = <&gcc GCC_QUPV3_WRAP0_S0_CLK>;
			clock-names = "se-clk";
			interconnects =
			<&clk_virt MASTER_QUP_CORE_0 &clk_virt SLAVE_QUP_CORE_0>,
			<&mem_noc MASTER_AMPSS_M0 &config_noc SLAVE_QUP_0>,
			<&system_noc MASTER_QUP_0 &mc_virt SLAVE_EBI_CH0>;
			interconnect-names = "qup-core",
					     "qup-config",
					     "qup-memory";
			pinctrl-0 = <&qup_i2c0_data>, <&qup_i2c0_clk>;
			pinctrl-1 = <&qup_i2c0_sleep>;
			pinctrl-names = "default",
					"sleep";
			dmas = <&gpi_dma0 0 0 QCOM_GPI_I2C 64 0>,
			       <&gpi_dma0 1 0 QCOM_GPI_I2C 64 0>;
			dma-names = "tx",
				    "rx";
			#address-cells = <1>;
			#size-cells = <0>;
			status = "disabled";
		};

		spi0: spi@4a80000 {
			compatible = "qcom,spi-geni";
			reg = <0x4a80000 0x4000>;
			reg-names = "se_phys";
			interrupts = <GIC_SPI 527 IRQ_TYPE_LEVEL_HIGH>;
			clocks = <&gcc GCC_QUPV3_WRAP0_S0_CLK>;
			clock-names = "se-clk";
			interconnects =
			<&clk_virt MASTER_QUP_CORE_0 &clk_virt SLAVE_QUP_CORE_0>,
			<&mem_noc MASTER_AMPSS_M0 &config_noc SLAVE_QUP_0>,
			<&system_noc MASTER_QUP_0 &mc_virt SLAVE_EBI_CH0>;
			interconnect-names = "qup-core",
					     "qup-config",
					     "qup-memory";
			pinctrl-0 = <&qup_spi0_miso>, <&qup_spi0_mosi>,
				    <&qup_spi0_clk>, <&qup_spi0_cs>;
			pinctrl-1 = <&qup_spi0_sleep>;
			pinctrl-names = "default",
					"sleep";
			dmas = <&gpi_dma0 0 0 QCOM_GPI_SPI 64 0>,
			       <&gpi_dma0 1 0 QCOM_GPI_SPI 64 0>;
			dma-names = "tx",
				    "rx";
			#address-cells = <1>;
			#size-cells = <0>;
			spi-max-frequency = <50000000>;
			status = "disabled";
		};

		uart0: serial@4a80000 {
			compatible = "qcom,geni-debug-uart";
			reg = <0x4a80000 0x4000>;
			reg-names = "se_phys";
			interrupts = <GIC_SPI 527 IRQ_TYPE_LEVEL_HIGH>;
			clocks = <&gcc GCC_QUPV3_WRAP0_S0_CLK>;
			clock-names = "se";
			interconnects =
			<&clk_virt MASTER_QUP_CORE_0 &clk_virt SLAVE_QUP_CORE_0>,
			<&mem_noc MASTER_AMPSS_M0 &config_noc SLAVE_QUP_0>,
			<&system_noc MASTER_QUP_0 &mc_virt SLAVE_EBI_CH0>;
			interconnect-names = "qup-core",
					     "qup-config",
					     "qup-memory";
			pinctrl-0 = <&qup_uart0_tx>, <&qup_uart0_rx>;
			pinctrl-1 = <&qup_uart0_sleep>;
			pinctrl-names = "default", "sleep";
			status = "disabled";
		};

		i2c1: i2c@4a84000 {
			compatible = "qcom,i2c-geni";
			reg = <0x4a84000 0x4000>;
			interrupts = <GIC_SPI 528 IRQ_TYPE_LEVEL_HIGH>;
			clocks = <&gcc GCC_QUPV3_WRAP0_S1_CLK>;
			clock-names = "se-clk";
			interconnects =
			<&clk_virt MASTER_QUP_CORE_0 &clk_virt SLAVE_QUP_CORE_0>,
			<&mem_noc MASTER_AMPSS_M0 &config_noc SLAVE_QUP_0>,
			<&system_noc MASTER_QUP_0 &mc_virt SLAVE_EBI_CH0>;
			interconnect-names = "qup-core",
					     "qup-config",
					     "qup-memory";
			pinctrl-0 = <&qup_i2c1_data>, <&qup_i2c1_clk>;
			pinctrl-1 = <&qup_i2c1_sleep>;
			pinctrl-names = "default",
					"sleep";
			dmas = <&gpi_dma0 0 1 QCOM_GPI_I2C 64 0>,
			       <&gpi_dma0 1 1 QCOM_GPI_I2C 64 0>;
			dma-names = "tx",
				    "rx";
			#address-cells = <1>;
			#size-cells = <0>;
			status = "disabled";
		};

		uart1: serial-a@4a84000 {
			compatible = "qcom,msm-geni-serial-hs";
			reg = <0x4a84000 0x4000>;
			reg-names = "se_phys";
			interrupts = <GIC_SPI 528 IRQ_TYPE_LEVEL_HIGH>;
			clocks = <&gcc GCC_QUPV3_WRAP0_S1_CLK>;
			clock-names = "se-clk";
			interconnects =
			<&clk_virt MASTER_QUP_CORE_0 &clk_virt SLAVE_QUP_CORE_0>,
			<&mem_noc MASTER_AMPSS_M0 &config_noc SLAVE_QUP_0>,
			<&system_noc MASTER_QUP_0 &mc_virt SLAVE_EBI_CH0>;
			interconnect-names = "qup-core",
					     "qup-config",
					     "qup-memory";
			pinctrl-0 = <&qup_uart1_tx>,<&qup_uart1_rx>;
			pinctrl-1 = <&qup_uart1_sleep>;
			pinctrl-names = "default", "sleep";
			qcom,suspend-ignore-children;
			status = "disabled";
		};

		i2c2: i2c@4a88000 {
			compatible = "qcom,i2c-geni";
			reg = <0x4a88000 0x4000>;
			interrupts = <GIC_SPI 529 IRQ_TYPE_LEVEL_HIGH>;
			clocks = <&gcc GCC_QUPV3_WRAP0_S2_CLK>;
			clock-names = "se-clk";
			interconnects =
			<&clk_virt MASTER_QUP_CORE_0 &clk_virt SLAVE_QUP_CORE_0>,
			<&mem_noc MASTER_AMPSS_M0 &config_noc SLAVE_QUP_0>,
			<&system_noc MASTER_QUP_0 &mc_virt SLAVE_EBI_CH0>;
			interconnect-names = "qup-core",
					     "qup-config",
					     "qup-memory";
			pinctrl-0 = <&qup_i2c2_data>, <&qup_i2c2_clk>;
			pinctrl-1 = <&qup_i2c2_sleep>;
			pinctrl-names = "default",
					"sleep";
			dmas = <&gpi_dma0 0 2 QCOM_GPI_I2C 64 0>,
			       <&gpi_dma0 1 2 QCOM_GPI_I2C 64 0>;
			dma-names = "tx",
				    "rx";
			#address-cells = <1>;
			#size-cells = <0>;
			status = "disabled";
		};

		spi2: spi@4a88000 {
			compatible = "qcom,spi-geni";
			reg = <0x4a88000 0x4000>;
			reg-names = "se_phys";
			interrupts = <GIC_SPI 529 IRQ_TYPE_LEVEL_HIGH>;
			clocks = <&gcc GCC_QUPV3_WRAP0_S2_CLK>;
			clock-names = "se-clk";
			interconnects =
			<&clk_virt MASTER_QUP_CORE_0 &clk_virt SLAVE_QUP_CORE_0>,
			<&mem_noc MASTER_AMPSS_M0 &config_noc SLAVE_QUP_0>,
			<&system_noc MASTER_QUP_0 &mc_virt SLAVE_EBI_CH0>;
			interconnect-names = "qup-core",
					     "qup-config",
					     "qup-memory";
			pinctrl-0 = <&qup_spi2_miso>, <&qup_spi2_mosi>,
				    <&qup_spi2_clk>, <&qup_spi2_cs>;
			pinctrl-1 = <&qup_spi2_sleep>;
			pinctrl-names = "default",
					"sleep";
			dmas = <&gpi_dma0 0 2 QCOM_GPI_SPI 64 0>,
			       <&gpi_dma0 1 2 QCOM_GPI_SPI 64 0>;
			dma-names = "tx",
				    "rx";
			#address-cells = <1>;
			#size-cells = <0>;
			spi-max-frequency = <50000000>;
			status = "disabled";
		};

		uart2: serial@4a88000 {
			compatible = "qcom,msm-geni-serial-hs";
			reg = <0x4a88000 0x4000>;
			reg-names = "se_phys";
			interrupts-extended = <&intc GIC_SPI 529 IRQ_TYPE_LEVEL_HIGH>,
					      <&tlmm 9 IRQ_TYPE_LEVEL_HIGH>;
			clocks = <&gcc GCC_QUPV3_WRAP0_S2_CLK>;
			clock-names = "se-clk";
			interconnects =
			<&clk_virt MASTER_QUP_CORE_0 &clk_virt SLAVE_QUP_CORE_0>,
			<&mem_noc MASTER_AMPSS_M0 &config_noc SLAVE_QUP_0>,
			<&system_noc MASTER_QUP_0 &mc_virt SLAVE_EBI_CH0>;
			interconnect-names = "qup-core",
					     "qup-config",
					     "qup-memory";
			pinctrl-0 = <&qup_uart2_default>;
			pinctrl-1 = <&qup_uart2_cts>, <&qup_uart2_rts>,
				    <&qup_uart2_tx>, <&qup_uart2_rx>;
			pinctrl-2 = <&qup_uart2_cts>, <&qup_uart2_rts>,
				    <&qup_uart2_tx>, <&qup_uart2_sleep>;
			pinctrl-3 = <&qup_uart2_default>;
			pinctrl-names = "default",
					"active",
					"sleep",
					"shutdown";
			qcom,suspend-ignore-children;
			status = "disabled";
		};

		i2c3: i2c@4a8c000 {
			compatible = "qcom,i2c-geni";
			reg = <0x4a8c000 0x4000>;
			interrupts = <GIC_SPI 530 IRQ_TYPE_LEVEL_HIGH>;
			clocks = <&gcc GCC_QUPV3_WRAP0_S3_CLK>;
			clock-names = "se-clk";
			interconnects =
			<&clk_virt MASTER_QUP_CORE_0 &clk_virt SLAVE_QUP_CORE_0>,
			<&mem_noc MASTER_AMPSS_M0 &config_noc SLAVE_QUP_0>,
			<&system_noc MASTER_QUP_0 &mc_virt SLAVE_EBI_CH0>;
			interconnect-names = "qup-core",
					     "qup-config",
					     "qup-memory";
			pinctrl-0 = <&qup_i2c3_data>, <&qup_i2c3_clk>;
			pinctrl-1 = <&qup_i2c3_sleep>;
			pinctrl-names = "default",
					"sleep";
			dmas = <&gpi_dma0 0 3 QCOM_GPI_I2C 64 0>,
			       <&gpi_dma0 1 3 QCOM_GPI_I2C 64 0>;
			dma-names = "tx",
				    "rx";
			#address-cells = <1>;
			#size-cells = <0>;
			status = "disabled";
		};

		uart3: serial@4a8c000 {
			compatible = "qcom,msm-geni-serial-hs";
			reg = <0x4a8c000 0x4000>;
			reg-names = "se_phys";
			interrupts = <GIC_SPI 530 IRQ_TYPE_LEVEL_HIGH>;
			clocks = <&gcc GCC_QUPV3_WRAP0_S3_CLK>;
			clock-names = "se-clk";
			interconnects =
			<&clk_virt MASTER_QUP_CORE_0 &clk_virt SLAVE_QUP_CORE_0>,
			<&mem_noc MASTER_AMPSS_M0 &config_noc SLAVE_QUP_0>,
			<&system_noc MASTER_QUP_0 &mc_virt SLAVE_EBI_CH0>;
			interconnect-names = "qup-core",
					     "qup-config",
					     "qup-memory";
			pinctrl-0 = <&qup_uart3_tx>,<&qup_uart3_rx>;
			pinctrl-1 = <&qup_uart3_sleep>;
			pinctrl-names = "default", "sleep";
			qcom,suspend-ignore-children;
			status = "disabled";
		};

		i2c4: i2c@4a90000 {
			compatible = "qcom,i2c-geni";
			reg = <0x4a90000 0x4000>;
			interrupts = <GIC_SPI 531 IRQ_TYPE_LEVEL_HIGH>;
			clocks = <&gcc GCC_QUPV3_WRAP0_S4_CLK>;
			clock-names = "se-clk";
			interconnects =
			<&clk_virt MASTER_QUP_CORE_0 &clk_virt SLAVE_QUP_CORE_0>,
			<&mem_noc MASTER_AMPSS_M0 &config_noc SLAVE_QUP_0>,
			<&system_noc MASTER_QUP_0 &mc_virt SLAVE_EBI_CH0>;
			interconnect-names = "qup-core",
					     "qup-config",
					     "qup-memory";
			pinctrl-0 = <&qup_i2c4_data>, <&qup_i2c4_clk>;
			pinctrl-1 = <&qup_i2c4_sleep>;
			pinctrl-names = "default",
					"sleep";
			dmas = <&gpi_dma0 0 4 QCOM_GPI_I2C 64 0x2>,
			       <&gpi_dma0 1 4 QCOM_GPI_I2C 64 0x2>;
			dma-names = "tx",
				    "rx";
			#address-cells = <1>;
			#size-cells = <0>;
			status = "disabled";
		};

		uart4: serial@4a90000 {
			compatible = "qcom,msm-geni-serial-hs";
			reg = <0x4a90000 0x4000>;
			reg-names = "se_phys";
			interrupts = <GIC_SPI 531 IRQ_TYPE_LEVEL_HIGH>;
			clocks = <&gcc GCC_QUPV3_WRAP0_S4_CLK>;
			clock-names = "se-clk";
			interconnects =
			<&clk_virt MASTER_QUP_CORE_0 &clk_virt SLAVE_QUP_CORE_0>,
			<&mem_noc MASTER_AMPSS_M0 &config_noc SLAVE_QUP_0>,
			<&system_noc MASTER_QUP_0 &mc_virt SLAVE_EBI_CH0>;
			interconnect-names = "qup-core",
					     "qup-config",
					     "qup-memory";
			pinctrl-0 = <&qup_uart4_tx>,<&qup_uart4_rx>;
			pinctrl-1 = <&qup_uart4_sleep>;
			pinctrl-names = "default", "sleep";
			qcom,suspend-ignore-children;
			status = "disabled";
		};

		i2c5: i2c@4a94000 {
			compatible = "qcom,i2c-geni";
			reg = <0x4a94000 0x4000>;
			interrupts = <GIC_SPI 532 IRQ_TYPE_LEVEL_HIGH>;
			clocks = <&gcc GCC_QUPV3_WRAP0_S5_CLK>;
			clock-names = "se-clk";
			interconnects =
			<&clk_virt MASTER_QUP_CORE_0 &clk_virt SLAVE_QUP_CORE_0>,
			<&mem_noc MASTER_AMPSS_M0 &config_noc SLAVE_QUP_0>,
			<&system_noc MASTER_QUP_0 &mc_virt SLAVE_EBI_CH0>;
			interconnect-names = "qup-core",
					     "qup-config",
					     "qup-memory";
			pinctrl-0 = <&qup_i2c5_data>, <&qup_i2c5_clk>;
			pinctrl-1 = <&qup_i2c5_sleep>;
			pinctrl-names = "default",
					"sleep";
			dmas = <&gpi_dma0 0 5 QCOM_GPI_I2C 64 0>,
			       <&gpi_dma0 1 5 QCOM_GPI_I2C 64 0>;
			dma-names = "tx",
				    "rx";
			#address-cells = <1>;
			#size-cells = <0>;
			status = "disabled";
		};

		spi5: spi@4a94000 {
			compatible = "qcom,spi-geni";
			reg = <0x4a94000 0x4000>;
			reg-names = "se_phys";
			interrupts = <GIC_SPI 532 IRQ_TYPE_LEVEL_HIGH>;
			clocks = <&gcc GCC_QUPV3_WRAP0_S5_CLK>;
			clock-names = "se-clk";
			interconnects =
			<&clk_virt MASTER_QUP_CORE_0 &clk_virt SLAVE_QUP_CORE_0>,
			<&mem_noc MASTER_AMPSS_M0 &config_noc SLAVE_QUP_0>,
			<&system_noc MASTER_QUP_0 &mc_virt SLAVE_EBI_CH0>;
			interconnect-names = "qup-core",
					     "qup-config",
					     "qup-memory";
			pinctrl-0 = <&qup_spi5_miso>, <&qup_spi5_mosi>,
				    <&qup_spi5_clk>, <&qup_spi5_cs>;
			pinctrl-1 = <&qup_spi5_sleep>;
			pinctrl-names = "default",
					"sleep";
			dmas = <&gpi_dma0 0 5 QCOM_GPI_SPI 64 0>,
			       <&gpi_dma0 1 5 QCOM_GPI_SPI 64 0>;
			dma-names = "tx",
				    "rx";
			#address-cells = <1>;
			#size-cells = <0>;
			spi-max-frequency = <50000000>;
			status = "disabled";
		};

		uart5: serial@4a94000 {
			compatible = "qcom,msm-geni-serial-hs";
			reg = <0x4a94000 0x4000>;
			reg-names = "se_phys";
			interrupts-extended = <&intc GIC_SPI 532 IRQ_TYPE_LEVEL_HIGH>,
					      <&tlmm 17 IRQ_TYPE_LEVEL_HIGH>;
			clocks = <&gcc GCC_QUPV3_WRAP0_S5_CLK>;
			clock-names = "se-clk";
			interconnects =
			<&clk_virt MASTER_QUP_CORE_0 &clk_virt SLAVE_QUP_CORE_0>,
			<&mem_noc MASTER_AMPSS_M0 &config_noc SLAVE_QUP_0>,
			<&system_noc MASTER_QUP_0 &mc_virt SLAVE_EBI_CH0>;
			interconnect-names = "qup-core",
					     "qup-config",
					     "qup-memory";
			pinctrl-0 = <&qup_uart5_default>;
			pinctrl-1 = <&qup_uart5_cts>, <&qup_uart5_rts>,
				    <&qup_uart5_tx>, <&qup_uart5_rx>;
			pinctrl-2 = <&qup_uart5_cts>, <&qup_uart5_rts>,
				    <&qup_uart5_tx>, <&qup_uart5_sleep>;
			pinctrl-3 = <&qup_uart5_default>;
			pinctrl-names = "default",
					"active",
					"sleep",
					"shutdown";
			qcom,suspend-ignore-children;
			status = "disabled";
		};

		i2c6: i2c@4a98000 {
			compatible = "qcom,i2c-geni";
			reg = <0x4a98000 0x4000>;
			interrupts = <GIC_SPI 533 IRQ_TYPE_LEVEL_HIGH>;
			clocks = <&gcc GCC_QUPV3_WRAP0_S6_CLK>;
			clock-names = "se-clk";
			interconnects =
			<&clk_virt MASTER_QUP_CORE_0 &clk_virt SLAVE_QUP_CORE_0>,
			<&mem_noc MASTER_AMPSS_M0 &config_noc SLAVE_QUP_0>,
			<&system_noc MASTER_QUP_0 &mc_virt SLAVE_EBI_CH0>;
			interconnect-names = "qup-core",
					     "qup-config",
					     "qup-memory";
			pinctrl-0 = <&qup_i2c6_data>, <&qup_i2c6_clk>;
			pinctrl-1 = <&qup_i2c6_sleep>;
			pinctrl-names = "default",
					"sleep";
			dmas = <&gpi_dma0 0 6 QCOM_GPI_I2C 64 0>,
			       <&gpi_dma0 1 6 QCOM_GPI_I2C 64 0>;
			dma-names = "tx",
				    "rx";
			#address-cells = <1>;
			#size-cells = <0>;
			status = "disabled";
		};

		spi6: spi@4a98000 {
			compatible = "qcom,spi-geni";
			reg = <0x4a98000 0x4000>;
			reg-names = "se_phys";
			interrupts = <GIC_SPI 533 IRQ_TYPE_LEVEL_HIGH>;
			clocks = <&gcc GCC_QUPV3_WRAP0_S6_CLK>;
			clock-names = "se-clk";
			interconnects =
			<&clk_virt MASTER_QUP_CORE_0 &clk_virt SLAVE_QUP_CORE_0>,
			<&mem_noc MASTER_AMPSS_M0 &config_noc SLAVE_QUP_0>,
			<&system_noc MASTER_QUP_0 &mc_virt SLAVE_EBI_CH0>;
			interconnect-names = "qup-core",
					     "qup-config",
					     "qup-memory";
			pinctrl-0 = <&qup_spi6_miso>, <&qup_spi6_mosi>,
				    <&qup_spi6_clk>, <&qup_spi6_cs>;
			pinctrl-1 = <&qup_spi6_sleep>;
			pinctrl-names = "default",
					"sleep";
			dmas = <&gpi_dma0 0 6 QCOM_GPI_SPI 64 0>,
			       <&gpi_dma0 1 6 QCOM_GPI_SPI 64 0>;
			dma-names = "tx",
				    "rx";
			#address-cells = <1>;
			#size-cells = <0>;
			spi-max-frequency = <50000000>;
			status = "disabled";
		};

		uart6: serial@4a98000 {
			compatible = "qcom,msm-geni-serial-hs";
			reg = <0x4a98000 0x4000>;
			reg-names = "se_phys";
			interrupts-extended = <&intc GIC_SPI 533 IRQ_TYPE_LEVEL_HIGH>,
					      <&tlmm 29 IRQ_TYPE_LEVEL_HIGH>;
			clocks = <&gcc GCC_QUPV3_WRAP0_S6_CLK>;
			clock-names = "se-clk";
			interconnects =
			<&clk_virt MASTER_QUP_CORE_0 &clk_virt SLAVE_QUP_CORE_0>,
			<&mem_noc MASTER_AMPSS_M0 &config_noc SLAVE_QUP_0>,
			<&system_noc MASTER_QUP_0 &mc_virt SLAVE_EBI_CH0>;
			interconnect-names = "qup-core",
					     "qup-config",
					     "qup-memory";
			pinctrl-0 = <&qup_uart6_default>;
			pinctrl-1 = <&qup_uart6_cts>, <&qup_uart6_rts>,
				    <&qup_uart6_tx>, <&qup_uart6_rx>;
			pinctrl-2 = <&qup_uart6_cts>, <&qup_uart6_rts>,
				    <&qup_uart6_tx>, <&qup_uart6_sleep>;
			pinctrl-3 = <&qup_uart6_default>;
			pinctrl-names = "default",
					"active",
					"sleep",
					"shutdown";
			qcom,suspend-ignore-children;
			status = "disabled";
		};

		i2c7: i2c@4a9c000 {
			compatible = "qcom,i2c-geni";
			reg = <0x4a9c000 0x4000>;
			interrupts = <GIC_SPI 534 IRQ_TYPE_LEVEL_HIGH>;
			clocks = <&gcc GCC_QUPV3_WRAP0_S7_CLK>;
			clock-names = "se-clk";
			interconnects =
			<&clk_virt MASTER_QUP_CORE_0 &clk_virt SLAVE_QUP_CORE_0>,
			<&mem_noc MASTER_AMPSS_M0 &config_noc SLAVE_QUP_0>,
			<&system_noc MASTER_QUP_0 &mc_virt SLAVE_EBI_CH0>;
			interconnect-names = "qup-core",
					     "qup-config",
					     "qup-memory";
			pinctrl-0 = <&qup_i2c7_data>, <&qup_i2c7_clk>;
			pinctrl-1 = <&qup_i2c7_sleep>;
			pinctrl-names = "default",
					"sleep";
			dmas = <&gpi_dma0 0 7 QCOM_GPI_I2C 64 0>,
			       <&gpi_dma0 1 7 QCOM_GPI_I2C 64 0>;
			dma-names = "tx",
				    "rx";
			#address-cells = <1>;
			#size-cells = <0>;
			status = "disabled";
		};

		uart7: serial@4a9c000 {
			compatible = "qcom,msm-geni-serial-hs";
			reg = <0x4a9c000 0x4000>;
			reg-names = "se_phys";
			interrupts = <GIC_SPI 534 IRQ_TYPE_LEVEL_HIGH>;
			clocks = <&gcc GCC_QUPV3_WRAP0_S7_CLK>;
			clock-names = "se-clk";
			interconnects =
			<&clk_virt MASTER_QUP_CORE_0 &clk_virt SLAVE_QUP_CORE_0>,
			<&mem_noc MASTER_AMPSS_M0 &config_noc SLAVE_QUP_0>,
			<&system_noc MASTER_QUP_0 &mc_virt SLAVE_EBI_CH0>;
			interconnect-names = "qup-core",
					     "qup-config",
					     "qup-memory";
			pinctrl-0 = <&qup_uart7_tx>,<&qup_uart7_rx>;
			pinctrl-1 = <&qup_uart7_sleep>;
			pinctrl-names = "default", "sleep";
			qcom,suspend-ignore-children;
			status = "disabled";
		};

		i2c8: i2c@4aa0000 {
			compatible = "qcom,i2c-geni";
			reg = <0x4aa0000 0x4000>;
			interrupts = <GIC_SPI 535 IRQ_TYPE_LEVEL_HIGH>;
			clocks = <&gcc GCC_QUPV3_WRAP0_S8_CLK>;
			clock-names = "se-clk";
			interconnects =
			<&clk_virt MASTER_QUP_CORE_0 &clk_virt SLAVE_QUP_CORE_0>,
			<&mem_noc MASTER_AMPSS_M0 &config_noc SLAVE_QUP_0>,
			<&system_noc MASTER_QUP_0 &mc_virt SLAVE_EBI_CH0>;
			interconnect-names = "qup-core",
					     "qup-config",
					     "qup-memory";
			pinctrl-0 = <&qup_i2c8_data>, <&qup_i2c8_clk>;
			pinctrl-1 = <&qup_i2c8_sleep>;
			pinctrl-names = "default",
					"sleep";
			dmas = <&gpi_dma0 0 8 QCOM_GPI_I2C 64 0>,
			       <&gpi_dma0 1 8 QCOM_GPI_I2C 64 0>;
			dma-names = "tx",
				    "rx";
			#address-cells = <1>;
			#size-cells = <0>;
			status = "disabled";
		};

		spi8: spi@4aa0000 {
			compatible = "qcom,spi-geni";
			reg = <0x4aa0000 0x4000>;
			reg-names = "se_phys";
			interrupts = <GIC_SPI 535 IRQ_TYPE_LEVEL_HIGH>;
			clocks = <&gcc GCC_QUPV3_WRAP0_S8_CLK>;
			clock-names = "se-clk";
			interconnects =
			<&clk_virt MASTER_QUP_CORE_0 &clk_virt SLAVE_QUP_CORE_0>,
			<&mem_noc MASTER_AMPSS_M0 &config_noc SLAVE_QUP_0>,
			<&system_noc MASTER_QUP_0 &mc_virt SLAVE_EBI_CH0>;
			interconnect-names = "qup-core",
					     "qup-config",
					     "qup-memory";
			pinctrl-0 = <&qup_spi8_miso>, <&qup_spi8_mosi>,
				    <&qup_spi8_clk>, <&qup_spi8_cs>;
			pinctrl-1 = <&qup_spi8_sleep>;
			pinctrl-names = "default",
					"sleep";
			dmas = <&gpi_dma0 0 8 QCOM_GPI_SPI 64 0>,
			       <&gpi_dma0 1 8 QCOM_GPI_SPI 64 0>;
			dma-names = "tx",
				    "rx";
			#address-cells = <1>;
			#size-cells = <0>;
			spi-max-frequency = <50000000>;
			status = "disabled";
		};

		uart8: serial@4aa0000 {
			compatible = "qcom,msm-geni-serial-hs";
			reg = <0x4aa0000 0x4000>;
			reg-names = "se_phys";
			interrupts-extended = <&intc GIC_SPI 535 IRQ_TYPE_LEVEL_HIGH>,
					      <&tlmm 25 IRQ_TYPE_LEVEL_HIGH>;
			clocks = <&gcc GCC_QUPV3_WRAP0_S8_CLK>;
			clock-names = "se-clk";
			interconnects =
			<&clk_virt MASTER_QUP_CORE_0 &clk_virt SLAVE_QUP_CORE_0>,
			<&mem_noc MASTER_AMPSS_M0 &config_noc SLAVE_QUP_0>,
			<&system_noc MASTER_QUP_0 &mc_virt SLAVE_EBI_CH0>;
			interconnect-names = "qup-core",
					     "qup-config",
					     "qup-memory";
			pinctrl-0 = <&qup_uart8_default_ctsrtsrx>,
				    <&qup_uart8_default_tx>;
			pinctrl-1 = <&qup_uart8_cts>, <&qup_uart8_rts>,
				    <&qup_uart8_tx>, <&qup_uart8_rx_active>;
			pinctrl-2 = <&qup_uart8_cts>, <&qup_uart8_rts>,
				    <&qup_uart8_tx>, <&qup_uart8_rx_wake>;
			pinctrl-3 = <&qup_uart8_default_ctsrtsrx>,
				    <&qup_uart8_default_tx>;
			pinctrl-names = "default",
					"active",
					"sleep",
					"shutdown";
			qcom,wakeup-byte = <0xFD>;
			qcom,suspend-ignore-children;
			status = "disabled";
		};

		spi9: spi@4aa4000 {
			compatible = "qcom,spi-geni";
			reg = <0x4aa4000 0x4000>;
			reg-names = "se_phys";
			interrupts = <GIC_SPI 536 IRQ_TYPE_LEVEL_HIGH>;
			clocks = <&gcc GCC_QUPV3_WRAP0_S9_CLK>;
			clock-names = "se-clk";
			interconnects =
			<&clk_virt MASTER_QUP_CORE_0 &clk_virt SLAVE_QUP_CORE_0>,
			<&mem_noc MASTER_AMPSS_M0 &config_noc SLAVE_QUP_0>,
			<&system_noc MASTER_QUP_0 &mc_virt SLAVE_EBI_CH0>;
			interconnect-names = "qup-core",
					     "qup-config",
					     "qup-memory";
			pinctrl-0 = <&qup_spi9_miso>, <&qup_spi9_mosi>,
				    <&qup_spi9_clk>, <&qup_spi9_cs>;
			pinctrl-1 = <&qup_spi9_sleep>;
			pinctrl-names = "default",
					"sleep";
			dmas = <&gpi_dma0 0 9 QCOM_GPI_SPI 64 0>,
			       <&gpi_dma0 1 9 QCOM_GPI_SPI 64 0>;
			dma-names = "tx",
				    "rx";
			#address-cells = <1>;
			#size-cells = <0>;
			spi-max-frequency = <50000000>;
			status = "disabled";
		};

		i2c9: i2c-a@4aa4000 {
			compatible = "qcom,i2c-geni";
			reg = <0x4aa4000 0x4000>;
			interrupts = <GIC_SPI 536 IRQ_TYPE_LEVEL_HIGH>;
			clocks = <&gcc GCC_QUPV3_WRAP0_S9_CLK>;
			clock-names = "se-clk";
			interconnects =
			<&clk_virt MASTER_QUP_CORE_0 &clk_virt SLAVE_QUP_CORE_0>,
			<&mem_noc MASTER_AMPSS_M0 &config_noc SLAVE_QUP_0>,
			<&system_noc MASTER_QUP_0 &mc_virt SLAVE_EBI_CH0>;
			interconnect-names = "qup-core",
					     "qup-config",
					     "qup-memory";
			pinctrl-0 = <&qup_i2c9_data>, <&qup_i2c9_clk>;
			pinctrl-1 = <&qup_i2c9_sleep>;
			pinctrl-names = "default",
					"sleep";
			dmas = <&gpi_dma0 0 9 QCOM_GPI_I2C 64 0>,
			       <&gpi_dma0 1 9 QCOM_GPI_I2C 64 0>;
			dma-names = "tx",
				    "rx";
			#address-cells = <1>;
			#size-cells = <0>;
			status = "disabled";
		};

		uart9: serial-a@4aa4000 {
			compatible = "qcom,msm-geni-serial-hs";
			reg = <0x4aa4000 0x4000>;
			reg-names = "se_phys";
			interrupts = <GIC_SPI 536 IRQ_TYPE_LEVEL_HIGH>;
			clocks = <&gcc GCC_QUPV3_WRAP0_S9_CLK>;
			clock-names = "se-clk";
			interconnects =
			<&clk_virt MASTER_QUP_CORE_0 &clk_virt SLAVE_QUP_CORE_0>,
			<&mem_noc MASTER_AMPSS_M0 &config_noc SLAVE_QUP_0>,
			<&system_noc MASTER_QUP_0 &mc_virt SLAVE_EBI_CH0>;
			interconnect-names = "qup-core",
					     "qup-config",
					     "qup-memory";
			pinctrl-0 = <&qup_uart9_tx>,<&qup_uart9_rx>;
			pinctrl-1 = <&qup_uart9_sleep>;
			pinctrl-names = "default", "sleep";
			qcom,suspend-ignore-children;
			status = "disabled";
		};

	};

	spmi_bus: spmi0_bus: qcom,spmi@1c0a700 {
		compatible = "qcom,spmi-pmic-arb";
		reg = <0x1c40000 0x10000>,
		      <0x1e00000 0x2000000>,
		      <0x3e00000 0x100000>,
		      <0x3f00000 0xa0000>,
		      <0x1c0a000 0x26000>;
		reg-names = "core", "chnls", "obsrvr", "intr", "cnfg";
		interrupts-extended = <&mpm 86 IRQ_TYPE_LEVEL_HIGH>;
		interrupt-names = "periph_irq";
		interrupt-controller;
		#interrupt-cells = <4>;
		#address-cells = <2>;
		#size-cells = <0>;
		cell-index = <0>;
		qcom,channel = <0>;
		qcom,ee = <0>;
		qcom,bus-id = <0>;
	};

	sdhc1_opp_table: sdhc1-opp-table {
		compatible = "operating-points-v2";

		opp-100000000 {
			opp-hz = /bits/ 64 <100000000>;
			opp-peak-kBps = <250000 133320>;
			opp-avg-kBps = <104000 0>;
		};

		opp-384000000 {
			opp-hz = /bits/ 64 <384000000>;
			opp-peak-kBps = <800000 300000>;
			opp-avg-kBps = <400000 0>;
		};
	};

	sdhc_1_dma_resv: sdhc_1_dma_resv_region {
		/*
		 * Restrict IOVA mappings for SDHC1 buffers to the 256 MB region
		 * from 0x40000000 - 0x4fffffff.
		 */
		iommu-addresses = <&sdhc_1 0x0 0x40000000>,
						  <&sdhc_1 0x50000000 0xb0000000>;
	};

	sdhc_1: sdhci@4744000 {
		compatible = "qcom,sdhci-msm-v5";
		status = "disabled";
		#address-cells = <2>;
		#size-cells = <2>;

		reg = <0x04744000 0x1000>,<0x04745000 0x1000>,<0x04748000 0x18000>;
		reg-names = "hc", "cqhci", "ice";

		iommus = <&apps_smmu 0xC0 0x0>;
		qcom,iommu-dma = "fastmap";

		/*
		 * iommu-addresses - Indicate the range of data addresses which will NOT
		 * be used in dma allocation.
		 *
		 * iommu-geometry -  This is specific for fastmap which Allow clients
		 * to save SMMU page table memory.
		 *
		 * The 2nd parameter indicates size of the smmu page table memory.
		 * If its exceeds beyond this size, last unused entry from page table
		 * memory will be invalidated.
		 *
		 * It's better to provide range of dma address, hence provide
		 * iommu-dma-addr-pool property along with iommu-geometry property.
		 */

		memory-region = <&sdhc_1_dma_resv>;
		qcom,iommu-geometry = <0x0 0x40000000 0x0 0x10000000>;

		interrupts = <GIC_SPI 348 IRQ_TYPE_LEVEL_HIGH>,
			<GIC_SPI 352 IRQ_TYPE_LEVEL_HIGH>;
		interrupt-names = "hc_irq", "pwr_irq";

		qcom,ice-use-hwkm;

		clocks = <&gcc GCC_SDCC1_APPS_CLK>,
			<&gcc GCC_SDCC1_AHB_CLK>,
			<&gcc GCC_SDCC1_ICE_CORE_CLK>;
		clock-names = "core", "iface","ice_core";

		qcom,ice-clk-rates = <300000000 100000000>;

		interconnects = <&system_noc MASTER_SDCC_1 &mc_virt SLAVE_EBI_CH0>,
				<&mem_noc MASTER_AMPSS_M0 &config_noc SLAVE_SDCC_1>;
		interconnect-names = "sdhc-ddr","cpu-sdhc";
		operating-points-v2 = <&sdhc1_opp_table>;

		/* DLL HSR settings. Refer go/hsr - <Target> DLL settings */
		qcom,dll-hsr-list = <0x000F642C 0x0 0x0 0x00010800 0x80040868>;

		bus-width = <8>;

		supports-cqe;

		cap-mmc-hw-reset;

		qcom,restore-after-cx-collapse;

		no-sd;
		no-sdio;

		non-removable;

		resets = <&gcc GCC_SDCC1_BCR>;
		reset-names = "core_reset";

		qos0 {
			mask = <0x08>;
			vote = <44>;
		};

		qos1 {
			mask = <0x07>;
			vote = <44>;
		};
	};

	sdhc_2_dma_resv: sdhc_2_dma_resv_region {
		/*
		 * Restrict IOVA mappings for SDHC2 buffers to the 256 MB region
		 * from 0x40000000 - 0x4fffffff.
		 */
		iommu-addresses = <&sdhc_2 0x0 0x40000000>,
				  <&sdhc_2 0x50000000 0xb0000000>;
	};

	sdhc_2: sdhci@4784000 {
		status = "disabled";

		compatible = "qcom,sdhci-msm-v5";
		reg = <0x4784000 0x1000>;
		reg-names = "hc";

		interrupts = <GIC_SPI 350 IRQ_TYPE_LEVEL_HIGH>,
				<GIC_SPI 353 IRQ_TYPE_LEVEL_HIGH>;
		interrupt-names = "hc_irq", "pwr_irq";

		bus-width = <4>;
		no-sdio;
		no-mmc;
		qcom,restore-after-cx-collapse;

		clocks = <&gcc GCC_SDCC2_AHB_CLK>,
			<&gcc GCC_SDCC2_APPS_CLK>;
		clock-names = "iface", "core";

		qcom,dll-config-list = <0x0007442c 0x0 0x10
					0x090106c0 0x80040868>;

		iommus = <&apps_smmu 0x0A0 0x0>;
		qcom,iommu-dma = "bypass";
		memory-region = <&sdhc_2_dma_resv>;
		qcom,iommu-geometry = <0x40000000 0x10000000>;

		interconnects = <&system_noc MASTER_SDCC_2 &mc_virt SLAVE_EBI_CH0>,
				<&mem_noc MASTER_AMPSS_M0 &config_noc SLAVE_SDCC_2>;
		interconnect-names = "sdhc-ddr","cpu-sdhc";
		operating-points-v2 = <&sdhc2_opp_table>;
	};

	sdhc2_opp_table: sdhc2-opp-table {
		compatible = "operating-points-v2";

		opp-100000000 {
			opp-hz = /bits/ 64 <100000000>;
			opp-peak-kBps = <160000 100000>;
			opp-avg-kBps = <50000 0>;
		};

		opp-202000000 {
			opp-hz = /bits/ 64 <202000000>;
			opp-peak-kBps = <200000 120000>;
			opp-avg-kBps = <104000 0>;
		};
	};

	qcom_rng: qrng@4454000 {
		compatible = "qcom,msm-rng";
		reg = <0x4454000 0x1000>;
		qcom,no-qrng-config;
		qcom,no-clock-support;
	};

	qcom,msm-imem@C11E000 {
		compatible = "qcom,msm-imem";
		reg = <0xC11E000 0x1000>;
		ranges = <0x0 0xC11E000 0x1000>;
		#address-cells = <1>;
		#size-cells = <1>;

		mem_dump_table@10 {
			compatible = "qcom,msm-imem-mem_dump_table";
			reg = <0x10 0x8>;
		};

		restart_reason@65c {
			compatible = "qcom,msm-imem-restart_reason";
			reg = <0x65c 0x4>;
		};

		dload_type@1c {
			compatible = "qcom,msm-imem-dload-type";
			reg = <0x1c 0x4>;
		};

		boot_stats@6b0 {
			compatible = "qcom,msm-imem-boot_stats";
			reg = <0x6b0 0x20>;
		};

		kaslr_offset@6d0 {
			compatible = "qcom,msm-imem-kaslr_offset";
			reg = <0x6d0 0xc>;
		};

		pil@94c {
			compatible = "qcom,pil-reloc-info";
			reg = <0x94c 0xc8>;
		};

		pil@6dc {
			compatible = "qcom,msm-imem-pil-disable-timeout";
			reg = <0x6dc 0x4>;
		};

		diag_dload@c8 {
			compatible = "qcom,msm-imem-diag-dload";
			reg = <0xc8 0xc8>;
		};

		modem_dsm@c98 {
			compatible = "qcom,msm-imem-mss-dsm";
			reg = <0xc98 0x10>;
		};
	};

	tcsr: syscon@3c0000 {
		compatible = "syscon";
		reg = <0x3c0000 0x40000>;
	};

	eud: qcom,msm-eud@1610000 {
		compatible = "qcom,msm-eud";
		interrupt-names = "eud_irq";
		interrupts = <GIC_SPI 189 IRQ_TYPE_LEVEL_HIGH>;
		reg = <0x1610000 0x2000>,
		      <0x1612000 0x1000>,
			<0x3E5018 0x4>;
		reg-names = "eud_base", "eud_mode_mgr2",
				"eud_tcsr_check_reg";
		qcom,secure-eud-en;
		qcom,eud-tcsr-check-enable;
		qcom,eud-clock-vote-req;
		clocks = <&gcc GCC_AHB2PHY_USB_CLK>;
		clock-names = "eud_ahb2phy_clk";
		status = "ok";
	};

	qfprom: qfprom@1B40000 {
		compatible = "qcom,shikra-qfprom", "qcom,qfprom";
		reg = <0x1B40000 0x7000>;
		#address-cells = <1>;
		#size-cells = <1>;
		read-only;
		ranges;
	};

	qcom_cedev: qcedev@1b20000 {
		compatible = "qcom,qcedev";
		reg = <0x1b20000 0x20000>,
			<0x1b04000 0x24000>;
		reg-names = "crypto-base","crypto-bam-base";
		interrupts = <GIC_SPI 247 IRQ_TYPE_LEVEL_HIGH>;
		qcom,bam-pipe-pair = <2>;
		qcom,ce-hw-instance = <0>;
		qcom,ce-device = <0>;
		qcom,ce-hw-shared;
		qcom,bam-ee = <0>;
		interconnect-names = "data_path";
		interconnects = <&system_noc MASTER_CRYPTO_CORE0 &mc_virt SLAVE_EBI_CH0>;
		clock-names =
			"core_clk_src", "core_clk",
			"iface_clk", "bus_clk";
		clocks =
			<&rpmcc RPM_SMD_CE1_CLK>,
			<&rpmcc RPM_SMD_CE1_CLK>,
			<&rpmcc RPM_SMD_CE1_CLK>,
			<&rpmcc RPM_SMD_CE1_CLK>;
		qcom,ce-opp-freq = <192000000>;
		qcom,smmu-s1-enable;
		iommus = <&apps_smmu 0x86 0x0011>,
			 <&apps_smmu 0x92 0x0>,
			 <&apps_smmu 0x96 0x0011>,
			 <&apps_smmu 0x98 0x0001>,
			 <&apps_smmu 0x9F 0x0>,
			 <&apps_smmu 0x84 0x0011>,
			 <&apps_smmu 0x94 0x0011>;
		qcom,iommu-dma = "atomic";

		qcom_cedev_ns_cb {
			compatible = "qcom,qcedev,context-bank";
			label = "ns_context";
			iommus = <&apps_smmu 0x92 0>,
				 <&apps_smmu 0x98 0x0001>,
				 <&apps_smmu 0x9F 0>,
				 <&apps_smmu 0x96 0x0011>,
				 <&apps_smmu 0x86 0x0011>;
		};

		qcom_cedev_s_cb {
			compatible = "qcom,qcedev,context-bank";
			label = "secure_context";
			iommus = <&apps_smmu 0x93 0>,
				<&apps_smmu 0x9C 0x0002>,
				<&apps_smmu 0x9E 0x0002>,
				<&apps_smmu 0x9D 0>;
			qcom,iommu-vmid = <0x9>; /* VMID_CP_BITSTREAM */
			qcom,secure-context-bank;
		};
	};

	qcom,sps {
		compatible = "qcom,msm-sps-v1_7-4k";
		qcom,pipe-attr-ee;
	};

	qcom_pmu: qcom,pmu {
		compatible = "qcom,pmu";
		qcom,pmu-events-tbl =
			< 0x0003 0xFF 0xFF 0xFF >,
			< 0x0008 0xFF 0xFF 0xFF >,
			< 0x0011 0xFF 0xFF 0xFF >,
			< 0x0017 0xFF 0xFF 0xFF >,
			< 0x0037 0xFF 0xFF 0xFF >;
	};

	ddr_freq_table: ddr-freq-table {
		qcom,freq-tbl =
			<  300000 >,
			<  547000 >,
			<  768000 >,
			< 1017000 >,
			< 1555000 >,
			< 1804000 >;
	};

	ddrqos_freq_table: ddrqos-freq-table {
		qcom,freq-tbl =
			< 1 >,
			< 2 >;
	};

	qcom_dcvs: qcom,dcvs {
		compatible = "qcom,dcvs";
		#address-cells = <1>;
		#size-cells = <1>;
		ranges;

		qcom_ddr_dcvs_hw: ddr {
			compatible = "qcom,dcvs-hw";
			qcom,dcvs-hw-type = <0>;
			qcom,bus-width = <4>;
			qcom,freq-tbl = <&ddr_freq_table>;

			ddr_dcvs_sp: sp {
				compatible = "qcom,dcvs-path";
				qcom,dcvs-path-type = <0>;
				interconnects = <&mem_noc MASTER_AMPSS_M0
						&mc_virt SLAVE_EBI_CH0>;
			};
		};

		qcom_l3_dcvs_hw: l3 {
			compatible = "qcom,dcvs-hw";
			qcom,dcvs-hw-type = <2>;
			qcom,bus-width = <32>;
			reg = <0xFD90000 0x1000>, <0xFD90100 0xa0>;
			reg-names = "l3-base", "l3tbl-base";

			l3_dcvs_sp: sp {
				compatible = "qcom,dcvs-path";
				qcom,dcvs-path-type = <0>;
				qcom,shared-offset = <0x0320>;
			};
		};

		qcom_ddrqos_dcvs_hw: ddrqos {
			compatible = "qcom,dcvs-hw";
			qcom,dcvs-hw-type = <3>;
			qcom,bus-width = <1>;
			qcom,freq-tbl = <&ddrqos_freq_table>;

			ddrqos_dcvs_sp: sp {
				compatible = "qcom,dcvs-path";
				qcom,dcvs-path-type = <0>;
				interconnects = <&mem_noc MASTER_AMPSS_M0
						&mc_virt SLAVE_EBI_CH0>;
			};
		};
	};

	qcom_memlat: qcom,memlat {
		compatible = "qcom,memlat";

		ddr {
			compatible = "qcom,memlat-grp";
			qcom,target-dev = <&qcom_ddr_dcvs_hw>;
			qcom,sampling-path = <&ddr_dcvs_sp>;
			qcom,miss-ev = <0x37>;

			silver {
				compatible = "qcom,memlat-mon";
				qcom,cpulist = <&CPU0 &CPU1 &CPU2>;
				qcom,sampling-enabled;
				qcom,cpufreq-memfreq-tbl =
					<  768000  300000 >,
					< 1017600  547000 >,
					< 1094400  768000 >,
					< 1497600 1017000 >,
					< 1612800 1555000 >,
					< 1804800 1804000 >;
			};

			gold {
				compatible = "qcom,memlat-mon";
				qcom,cpulist = <&CPU3>;
				qcom,sampling-enabled;
				qcom,cpufreq-memfreq-tbl =
					< 1017600  547000 >,
					< 1190400  768000 >,
					< 1497600 1017000 >,
					< 1708800 1555000 >,
					< 1900800 1804000 >;
			};

			silver-compute {
				compatible = "qcom,memlat-mon";
				qcom,cpulist = <&CPU0 &CPU1 &CPU2>;
				qcom,cpufreq-memfreq-tbl =
					< 1094400 300000 >,
					< 1497600 547000 >,
					< 1804800 768000 >;
				qcom,sampling-enabled;
				qcom,compute-mon;
			};

			gold-compute {
				compatible = "qcom,memlat-mon";
				qcom,cpulist = <&CPU3>;
				qcom,sampling-enabled;
				qcom,compute-mon;
				qcom,cpufreq-memfreq-tbl =
					<  768000  300000 >,
					< 1190400  547000 >,
					< 1497600  768000 >,
					< 1900800 1017000 >;
			};
		};

		l3 {
			compatible = "qcom,memlat-grp";
			qcom,target-dev = <&qcom_l3_dcvs_hw>;
			qcom,sampling-path = <&l3_dcvs_sp>;
			qcom,miss-ev = <0x03>;

			silver {
				compatible = "qcom,memlat-mon";
				qcom,cpulist = <&CPU0 &CPU1 &CPU2>;
				qcom,cpufreq-memfreq-tbl =
					<  768000  556800 >,
					< 1017600  806400 >,
					< 1094400  940800 >,
					< 1497600 1209600 >,
					< 1612800 1344000 >,
					< 1804800 1363200 >;
				qcom,sampling-enabled;
			};

			gold {
				compatible = "qcom,memlat-mon";
				qcom,cpulist = <&CPU3>;
				qcom,cpufreq-memfreq-tbl =
					<  768000  556800 >,
					< 1017600  806400 >,
					< 1190400  940800 >,
					< 1497600 1209600 >,
					< 1708800 1344000 >,
					< 1900800 1363200 >;
				qcom,sampling-enabled;
			};

			silver-compute {
				compatible = "qcom,memlat-mon";
				qcom,cpulist = <&CPU0 &CPU1 &CPU2>;
				qcom,cpufreq-memfreq-tbl =
					<  768000 556800 >,
					< 1612800 806400 >;
				qcom,sampling-enabled;
				qcom,compute-mon;
			};

			gold-compute {
				compatible = "qcom,memlat-mon";
				qcom,cpulist = <&CPU3>;
				qcom,cpufreq-memfreq-tbl =
					<  768000 556800 >,
					< 1900800 806400 >;
				qcom,sampling-enabled;
				qcom,compute-mon;
			};
		};

		ddrqos {
			compatible = "qcom,memlat-grp";
			qcom,target-dev = <&qcom_ddrqos_dcvs_hw>;
			qcom,sampling-path = <&ddrqos_dcvs_sp>;
			qcom,miss-ev = <0x37>;

			ddrqos_gold_lat: gold {
				compatible = "qcom,memlat-mon";
				qcom,cpulist = <&CPU3>;
				qcom,cpufreq-memfreq-tbl =
					<  300000 1 >,
					< 3000000 2 >;
				qcom,sampling-enabled;
			};
		};
	};

	bwmon_ddr: qcom,bwmon-ddr@00C91000 {
		compatible = "qcom,bwmon5";
		reg = <0x00C91000 0x1000>;
		reg-names = "base";
		interrupts = <GIC_SPI 468 IRQ_TYPE_LEVEL_HIGH>;
		qcom,hw-timer-hz = <19200000>;
		qcom,target-dev = <&qcom_ddr_dcvs_hw>;
		qcom,count-unit = <0x10000>;
	};

	modem_pas: remoteproc-mss@06080000 {
		compatible = "qcom,shikra-modem-pas";
		reg = <0x06080000 0x10000>;
		status = "ok";

		cx-supply = <&VDD_CX_LEVEL>;
		cx-uV-uA = <RPM_SMD_REGULATOR_LEVEL_TURBO 100000>;
		mx-supply = <&VDD_MX_LEVEL>;
		mx-uV-uA = <RPM_SMD_REGULATOR_LEVEL_NOM_PLUS 100000>;
		reg-names = "cx", "mx";

		clocks = <&rpmcc RPM_SMD_XO_CLK_SRC>;
		clock-names = "xo";

		interconnects = <&mem_noc MASTER_AMPSS_M0 &mc_virt SLAVE_EBI_CH0>,
				<&system_noc MASTER_CRYPTO_CORE0 &mc_virt SLAVE_EBI_CH0>;

		interconnect-names = "rproc_ddr", "crypto_ddr";

		firmware-name = "modem.mdt";

		memory-region = <&mpss_wlan_mem>;

		/* Inputs from mss */
		interrupts-extended = <&intc GIC_SPI 307 IRQ_TYPE_EDGE_RISING>,
					<&modem_smp2p_in 0 0>,
					<&modem_smp2p_in 2 0>,
					<&modem_smp2p_in 1 0>,
					<&modem_smp2p_in 3 0>,
					<&modem_smp2p_in 7 0>;

		interrupt-names = "wdog",
				"fatal",
				"handover",
				"ready",
				"stop-ack",
				"shutdown-ack";

		/* Outputs to mss */
		qcom,smem-states = <&modem_smp2p_out 0>;
		qcom,smem-state-names = "stop";

		remoteproc_modem_glink: glink-edge {
			qcom,remote-pid = <1>;
			transport = "smem";
			mboxes = <&apcs_glb 12>;
			mbox-names = "mpss_smem";
			interrupts = <GIC_SPI 68 IRQ_TYPE_EDGE_RISING>;

			label = "modem";
			qcom,glink-label = "mpss";

			qcom,modem_qrtr {
				qcom,glink-channels = "IPCRTR";
				qcom,low-latency;
				qcom,intents = <0x800  5
						0x2000 3
						0x4400 2>;
			};

			qcom,msm_fastrpc_rpmsg {
				compatible = "qcom,msm-fastrpc-rpmsg";
				qcom,glink-channels = "fastrpcglink-apps-dsp";
				qcom,intents = <0x64 64>;
			};

			qcom,modem_ds {
				qcom,glink-channels = "DS";
				qcom,intents = <0x4000 0x2>;
			};

			qcom,modem_glink_ssr {
				qcom,glink-channels = "glink_ssr";
			};
		};
	};

	cdsp_pas: remoteproc-cdsp@0B300000 {
		compatible = "qcom,shikra-cdsp-pas";
		reg = <0x0B300000 0x4040>;
		status = "ok";

		cx-supply = <&VDD_CX_LEVEL>;
		cx-uV-uA = <RPM_SMD_REGULATOR_LEVEL_TURBO 100000>;
		reg-names = "cx";

		clocks = <&rpmcc RPM_SMD_XO_CLK_SRC>;
		clock-names = "xo";

		interconnects = <&mem_noc MASTER_AMPSS_M0 &mc_virt SLAVE_EBI_CH0>,
				<&system_noc MASTER_CRYPTO_CORE0 &mc_virt SLAVE_EBI_CH0>;

		interconnect-names = "rproc_ddr", "crypto_ddr";

		firmware-name = "cdsp.mdt";
		memory-region = <&cdsp_mem>;

		/* Inputs from turing */
		interrupts-extended = <&intc GIC_SPI 265 IRQ_TYPE_EDGE_RISING>,
					<&cdsp_smp2p_in 0 0>,
					<&cdsp_smp2p_in 2 0>,
					<&cdsp_smp2p_in 1 0>,
					<&cdsp_smp2p_in 3 0>,
					<&cdsp_smp2p_in 7 0>;

		interrupt-names = "wdog",
				"fatal",
				"handover",
				"ready",
				"stop-ack",
				"shutdown-ack";

		/* Outputs to turing */
		qcom,smem-states = <&cdsp_smp2p_out 0>;
		qcom,smem-state-names = "stop";

		remoteproc_cdsp_glink: glink-edge {
			qcom,remote-pid = <5>;
			transport = "smem";
			mboxes = <&apcs_glb 4>;
			mbox-names = "cdsp_smem";
			interrupts = <GIC_SPI 261 IRQ_TYPE_EDGE_RISING>;

			label = "cdsp";
			qcom,glink-label = "cdsp";

			qcom,cdsp_qrtr {
				qcom,glink-channels = "IPCRTR";
				qcom,intents = <0x800  5
						0x2000 3
						0x4400 2>;
			};

			fastrpc {
				compatible = "qcom,fastrpc";
				qcom,glink-channels = "fastrpcglink-apps-dsp";
				label = "cdsp";
				#address-cells = <1>;
				#size-cells = <0>;

				compute-cb@1 {
					compatible = "qcom,fastrpc-compute-cb";
					reg = <1>;
					iommus = <&apps_smmu 0x0201 0x0000>;
				};

				compute-cb@2 {
					compatible = "qcom,fastrpc-compute-cb";
					reg = <2>;
					iommus = <&apps_smmu 0x0202 0x0000>;
				};

				compute-cb@3 {
					compatible = "qcom,fastrpc-compute-cb";
					reg = <3>;
					iommus = <&apps_smmu 0x0203 0x0000>;
				};

				compute-cb@4 {
					compatible = "qcom,fastrpc-compute-cb";
					reg = <4>;
					iommus = <&apps_smmu 0x0204 0x0000>;
				};

				compute-cb@5 {
					compatible = "qcom,fastrpc-compute-cb";
					reg = <5>;
					iommus = <&apps_smmu 0x0205 0x0000>;
				};

				compute-cb@6 {
					compatible = "qcom,fastrpc-compute-cb";
					reg = <6>;
					iommus = <&apps_smmu 0x0206 0x0000>;
				};

			};
		};
	};

	dload_mode {
		compatible = "qcom,dload-mode";
	};

	lpaicp_pas: remoteproc-lpaicp@0B800000 {
		compatible = "qcom,shikra-lpaicp-pas";
		reg = <0x0B800000 0x200000>;
		status = "ok";

		cx-supply = <&VDD_CX_LEVEL>;
		cx-uV-uA = <RPM_SMD_REGULATOR_LEVEL_TURBO 100000>;
		mx-supply = <&VDD_MX_LEVEL>;
		mx-uV-uA = <RPM_SMD_REGULATOR_LEVEL_NOM_PLUS 100000>;
		reg-names = "cx", "mx";

		clocks = <&rpmcc RPM_SMD_XO_CLK_SRC>;
		clock-names = "xo";

		firmware-name = "lpaicp.mbn", "lpaicp_dtb.mbn";

		memory-region = <&lmcu_mem &lmcu_dtb_mem>;

		/* Inputs from lpaicp */
		interrupts-extended = <&intc GIC_SPI 257 IRQ_TYPE_EDGE_RISING>,
					<&lmcu_smp2p_in 0 0>,
					<&lmcu_smp2p_in 2 0>,
					<&lmcu_smp2p_in 1 0>,
					<&lmcu_smp2p_in 3 0>;

		interrupt-names = "wdog",
				"fatal",
				"handover",
				"ready",
				"stop-ack";

		/* Outputs to lpaicp */
		qcom,smem-states = <&lmcu_smp2p_out 0>;
		qcom,smem-state-names = "stop";

		remoteproc_lmcu_glink: glink-edge {
			qcom,remote-pid = <26>;
			transport = "smem";
			mboxes = <&apcs_glb 9>;
			mbox-names = "lmcu_smem";
			interrupts = <GIC_SPI 286 IRQ_TYPE_EDGE_RISING>;

			label = "lmcu";
			qcom,glink-label = "lpaicp";

			qcom,lmcu_qrtr {
				qcom,glink-channels = "IPCRTR";
				qcom,intents = <0x800  5
						0x2000 3
						0x4400 2>;
			};

			qcom,glinkpkt-lpaicp-qsh-0 {
				qcom,glink-channels = "qsh_1_0";
				qcom,intents = <0x1000 3
						0x3E8  7>;
			};

			qcom,glinkpkt-lpaicp-qsh-1 {
				qcom,glink-channels = "qsh_1_1";
				qcom,intents = <0x1000 3
						0x3E8  7>;
			};

			qcom,glinkpkt-lpaicp-qsh-2 {
				qcom,glink-channels = "qsh_1_2";
				qcom,intents = <0x1000 3
						0x3E8  7>;
			};

			qcom,glinkpkt-lpaicp-qsh-3 {
				qcom,glink-channels = "qsh_1_3";
				qcom,intents = <0x1000 3
						0x3E8  7>;
			};

			qcom,glinkpkt-lpaicp-qsh-4 {
				qcom,glink-channels = "qsh_1_4";
				qcom,intents = <0x1000 3
						0x3E8  7>;
			};

			qcom,glinkpkt-lpaicp-qsh-5 {
				qcom,glink-channels = "qsh_1_5";
				qcom,intents = <0x1000 3
						0x3E8  7>;
			};

			qcom,glinkpkt-lpaicp-qsh-6 {
				qcom,glink-channels = "qsh_1_6";
				qcom,intents = <0x1000 3
						0x3E8  7>;
			};

			qcom,glinkpkt-lpaicp-qsh-7 {
				qcom,glink-channels = "qsh_1_7";
				qcom,intents = <0x1000 3
						0x3E8  7>;
			};

			qcom,glinkpkt-lpaicp-qsh-8 {
				qcom,glink-channels = "qsh_1_8";
				qcom,intents = <0x1000 3
						0x3E8  7>;
			};
		};
	};

	qcom_glinkpkt: qcom,glinkpkt {
		compatible = "qcom,glinkpkt";

		qcom,glinkpkt-ctrl-cdsp {
				qcom,glinkpkt-edge = "cdsp";
				qcom,glinkpkt-ch-name = "LOOPBACK_CTL_CDSP";
				qcom,glinkpkt-dev-name = "glink_pkt_ctrl_cdsp";
		};

		qcom,glinkpkt-data-cdsp {
				qcom,glinkpkt-edge = "cdsp";
				qcom,glinkpkt-ch-name = "LOOPBACK_DATA_CDSP";
				qcom,glinkpkt-dev-name = "glink_pkt_data_cdsp";
		};

		qcom,glinkpkt-ctrl-lpass {
				qcom,glinkpkt-edge = "lpass";
				qcom,glinkpkt-ch-name = "LOOPBACK_CTL_LPASS";
				qcom,glinkpkt-dev-name = "glink_pkt_ctrl_lpass";
		};

		qcom,glinkpkt-data-lpass {
				qcom,glinkpkt-edge = "lpass";
				qcom,glinkpkt-ch-name = "LOOPBACK_DATA_LPASS";
				qcom,glinkpkt-dev-name = "glink_pkt_data_lpass";
		};

		qcom,glinkpkt-ctrl-mpss {
				qcom,glinkpkt-edge = "mpss";
				qcom,glinkpkt-ch-name = "LOOPBACK_CTL_MPSS";
				qcom,glinkpkt-dev-name = "glink_pkt_ctrl_mpss";
		};

		qcom,glinkpkt-data-mpss {
				qcom,glinkpkt-edge = "mpss";
				qcom,glinkpkt-ch-name = "LOOPBACK_DATA_MPSS";
				qcom,glinkpkt-dev-name = "glink_pkt_data_mpss";
		};

		qcom,glinkpkt-ctrl-lmcu {
				qcom,glinkpkt-edge = "lmcu";
				qcom,glinkpkt-ch-name = "LOOPBACK_CTL_LMCU";
				qcom,glinkpkt-dev-name = "glink_pkt_ctrl_lmcu";
		};

		qcom,glinkpkt-data-lmcu {
				qcom,glinkpkt-edge = "lmcu";
				qcom,glinkpkt-ch-name = "LOOPBACK_DATA_LMCU";
				qcom,glinkpkt-dev-name = "glink_pkt_data_lmcu";
		};

		qcom,glinkpkt-lpaicp-qsh-0 {
			qcom,glinkpkt-edge = "lpaicp";
			qcom,glinkpkt-ch-name = "qsh_1_0";
			qcom,glinkpkt-dev-name = "glinkpkt_lpaicp_qsh_1_0";
			qcom,glinkpkt-enable-ch-close;
		};

		qcom,glinkpkt-lpaicp-qsh-1 {
			qcom,glinkpkt-edge = "lpaicp";
			qcom,glinkpkt-ch-name = "qsh_1_1";
			qcom,glinkpkt-dev-name = "glinkpkt_lpaicp_qsh_1_1";
			qcom,glinkpkt-enable-ch-close;
		};

		qcom,glinkpkt-lpaicp-qsh-2 {
			qcom,glinkpkt-edge = "lpaicp";
			qcom,glinkpkt-ch-name = "qsh_1_2";
			qcom,glinkpkt-dev-name = "glinkpkt_lpaicp_qsh_1_2";
			qcom,glinkpkt-enable-ch-close;
		};

		qcom,glinkpkt-lpaicp-qsh-3 {
			qcom,glinkpkt-edge = "lpaicp";
			qcom,glinkpkt-ch-name = "qsh_1_3";
			qcom,glinkpkt-dev-name = "glinkpkt_lpaicp_qsh_1_3";
			qcom,glinkpkt-enable-ch-close;
		};

		qcom,glinkpkt-lpaicp-qsh-4 {
			qcom,glinkpkt-edge = "lpaicp";
			qcom,glinkpkt-ch-name = "qsh_1_4";
			qcom,glinkpkt-dev-name = "glinkpkt_lpaicp_qsh_1_4";
			qcom,glinkpkt-enable-ch-close;
		};

		qcom,glinkpkt-lpaicp-qsh-5 {
			qcom,glinkpkt-edge = "lpaicp";
			qcom,glinkpkt-ch-name = "qsh_1_5";
			qcom,glinkpkt-dev-name = "glinkpkt_lpaicp_qsh_1_5";
			qcom,glinkpkt-enable-ch-close;
		};

		qcom,glinkpkt-lpaicp-qsh-6 {
			qcom,glinkpkt-edge = "lpaicp";
			qcom,glinkpkt-ch-name = "qsh_1_6";
			qcom,glinkpkt-dev-name = "glinkpkt_lpaicp_qsh_1_6";
			qcom,glinkpkt-enable-ch-close;
		};

		qcom,glinkpkt-lpaicp-qsh-7 {
			qcom,glinkpkt-edge = "lpaicp";
			qcom,glinkpkt-ch-name = "qsh_1_7";
			qcom,glinkpkt-dev-name = "glinkpkt_lpaicp_qsh_1_7";
			qcom,glinkpkt-enable-ch-close;
		};

		qcom,glinkpkt-lpaicp-qsh-8 {
			qcom,glinkpkt-edge = "lpaicp";
			qcom,glinkpkt-ch-name = "qsh_1_8";
			qcom,glinkpkt-dev-name = "glinkpkt_lpaicp_qsh_1_8";
			qcom,glinkpkt-enable-ch-close;
		};

		qcom,glinkpkt-data40-cntl {
			qcom,glinkpkt-edge = "mpss";
			qcom,glinkpkt-ch-name = "DATA40_CNTL";
			qcom,glinkpkt-dev-name = "smdcntl8";
		};

		qcom,glinkpkt-data1 {
			qcom,glinkpkt-edge = "mpss";
			qcom,glinkpkt-ch-name = "DATA1";
			qcom,glinkpkt-dev-name = "smd7";
		};

		qcom,glinkpkt-data2 {
			qcom,glinkpkt-edge = "mpss";
			qcom,glinkpkt-ch-name = "DATA2";
			qcom,glinkpkt-dev-name = "at_mdm0";
		};

		qcom,glinkpkt-data4 {
			qcom,glinkpkt-edge = "mpss";
			qcom,glinkpkt-ch-name = "DATA4";
			qcom,glinkpkt-dev-name = "smd8";
		};

		qcom,glinkpkt-data11 {
			qcom,glinkpkt-edge = "mpss";
			qcom,glinkpkt-ch-name = "DATA11";
			qcom,glinkpkt-dev-name = "smd11";
		};
	};

	restart@440b000 {
		compatible = "qcom,pshold";
		reg = <0x440b000 0x4>, <0x03d3000 0x4>;
		reg-names = "pshold-base", "tcsr-boot-misc-detect";
	};

	gunyah-cma-mem {
		compatible = "gunyah-cma-vm-mem";
		memory-region = <&trust_ui_vm_mem &oem_vm_mem>;
		memory-region-names = "trustedvm_cma" , "oemvm_cma";
	};

	qcom,qrtr-gunyah-oemvm {
		compatible = "qcom,qrtr-gunyah";
		qcom,master;
		gunyah-label = <0x108>;
		peer-name = <4>;
	};

	qcom,test-dbl-tuivm {
		compatible = "qcom,gh-dbl";
		qcom,label = <0x104>;
	};

	qcom,test-dbl-oemvm {
		compatible = "qcom,gh-dbl";
		qcom,label = <0x105>;
	};

	qcom,test-msgq-tuivm {
		compatible = "qcom,gh-msgq-test";
		gunyah-label = <0x104>;
		qcom,primary;
	};

	qcom,test-msgq-oemvm {
		compatible = "qcom,gh-msgq-test";
		gunyah-label = <0x105>;
		qcom,primary;
	};

	qcom,qrtr-gunyah-tuivm {
		compatible = "qcom,qrtr-gunyah";
		qcom,master;
		gunyah-label = <0x103>;
		peer-name = <2>;
	};

	tlmm-vm-mem-access {
		compatible = "qcom,tlmm-vm-mem-access";
		qcom,master;
		tuivm {
			qcom,label = <0x08>;
			qcom,vmid = <45>;
			tlmm-vm-gpio-list = <&tlmm 12 0 &tlmm 13 0>;
		};
	};

	qcom,gh-qtimer@F42B000 {
		compatible = "qcom,gh-qtmr";
		reg = <0x0 0x0F42B000 0x0 0x1000>;
		reg-names = "qtmr-base";
		interrupts = <GIC_SPI 13 IRQ_TYPE_LEVEL_HIGH>;
		interrupt-names = "qcom,qtmr-intr";
		qcom,primary;
	};

	qcom,gunyah-panic-notifier {
		compatible = "qcom,gh-panic-notifier";
		qcom,primary-vm;
		gunyah-label = <0x109>;
		peer-name = <2>;
		memory-region = <&vm_comm_mem>;
		shared-buffer-size = <0x1000>;
	};

	dmesg-dump {
		compatible = "qcom,dmesg-dump";
		qcom,primary-vm;
		gunyah-label = <0x107>;
		peer-name = <2>;
		memory-region = <&vm_comm_mem>;
		shared-buffer-size = <0x1000>;
	};

	cache-controller@e00000 {
		compatible = "qcom,shikra-llcc";
		reg = <0x0e00000 0x80000>,
		      <0x0f00000 0x80000>,
		      <0x1000000 0x80000>;
		reg-names = "llcc0_base", "llcc1_base", "llcc_broadcast_or_base";
		cap-based-alloc-and-pwr-collapse;
		interrupts = <GIC_SPI 539 IRQ_TYPE_LEVEL_HIGH>,
					<GIC_SPI 538 IRQ_TYPE_LEVEL_HIGH>;
		status = "okay";
	};

};

#include "shikra-pinctrl.dtsi"
#include "shikra-reserved-memory.dtsi"
#include "msm-arm-smmu-shikra.dtsi"
#include "shikra-dma-heaps.dtsi"
#include "shikra-thermal.dtsi"
#include "msm-rdbg-shikra.dtsi"
#include "shikra-walt.dtsi"
#include "shikra-debug.dtsi"
#include "shikra-coresight.dtsi"

&reserved_memory {
	#address-cells = <2>;
	#size-cells = <2>;
	ranges;
	/* global autoconfigured region for contiguous allocations */
    system_cma: linux,cma {
		compatible = "shared-dma-pool";
		alloc-ranges = <0x0 0x00000000 0x0 0xffffffff>;
		reusable;
		alignment = <0x0 0x400000>;
		size = <0x0 0x1000000>;
		linux,cma-default;
	};

	non_secure_display_memory: non_secure_display_region {
		compatible = "shared-dma-pool";
		reusable;
		alloc-ranges = <0x0 0x00000000 0x0 0xffffffff>;
		size = <0x0 0xa400000>;
		alignment = <0x0 0x400000>;
	};

	secure_display_memory: secure_display_region {
		compatible = "shared-dma-pool";
		alloc-ranges = <0 0x00000000 0 0xffffffff>;
		reusable;
		alignment = <0 0x400000>;
		size = <0 0x5c00000>;
	};

	qseecom_mem: qseecom_region {
		compatible = "shared-dma-pool";
		alloc-ranges = <0x0 0x00000000 0x0 0xffffffff>;
		reusable;
		alignment = <0x0 0x400000>;
		size = <0x0 0x1400000>;
	};

	qseecom_ta_mem: qseecom_ta_region {
		compatible = "shared-dma-pool";
		alloc-ranges = <0x0 0x00000000 0x0 0xffffffff>;
		reusable;
		alignment = <0x0 0x400000>;
		size = <0x0 0x1000000>;
	};

	vm_comm_mem: vm_comm_mem_region {
		compatible = "shared-dma-pool";
		alloc-ranges = <0x0 0x00000000 0x0 0xffffffff>;
		reusable;
		alignment = <0x0 0x400000>;
		size = <0x0 0x800000>;
	};
};

&tlmm {
	qup_i2c0_clk: qup_i2c0_clk-state {
		pins = "gpio3";
		function = "qup0_se0_l1";
	};

	qup_i2c0_data: qup_i2c0_data-state {
		pins = "gpio2";
		function = "qup0_se0_l0";
	};

	qup_i2c0_sleep: qup_i2c0_sleep-state {
		pins = "gpio2", "gpio3";
		function = "gpio";
	};

	qup_i2c1_clk: qup_i2c1_clk-state {
		pins = "gpio4";
		function = "qup0_se1_l1";
	};

	qup_i2c1_data: qup_i2c1_data-state {
		pins = "gpio5";
		function = "qup0_se1_l0";
	};

	qup_i2c1_sleep: qup_i2c1_sleep-state {
		pins = "gpio5", "gpio4";
		function = "gpio";
	};

	qup_i2c2_clk: qup_i2c2_clk-state {
		pins = "gpio7";
		function = "qup0_se2_l1";
	};

	qup_i2c2_data: qup_i2c2_data-state {
		pins = "gpio6";
		function = "qup0_se2_l0";
	};

	qup_i2c2_sleep: qup_i2c2_sleep-state {
		pins = "gpio6", "gpio7";
		function = "gpio";
	};

	qup_i2c3_clk: qup_i2c3_clk-state {
		pins = "gpio11";
		function = "qup0_se3_l1";
	};

	qup_i2c3_data: qup_i2c3_data-state {
		pins = "gpio10";
		function = "qup0_se3_l0";
	};

	qup_i2c3_sleep: qup_i2c3_sleep-state {
		pins = "gpio10", "gpio11";
		function = "gpio";
	};

	qup_i2c4_clk: qup_i2c4_clk-state {
		pins = "gpio13";
		function = "qup0_se4_l1";
	};

	qup_i2c4_data: qup_i2c4_data-state {
		pins = "gpio12";
		function = "qup0_se4_l0";
	};

	qup_i2c4_sleep: qup_i2c4_sleep-state {
		pins = "gpio12", "gpio13";
		function = "gpio";
	};

	qup_i2c5_clk: qup_i2c5_clk-state {
		pins = "gpio15";
		function = "qup0_se5_l1";
	};

	qup_i2c5_data: qup_i2c5_data-state {
		pins = "gpio14";
		function = "qup0_se5_l0";
	};

	qup_i2c5_sleep: qup_i2c5_sleep-state {
		pins = "gpio14", "gpio15";
		function = "gpio";
	};

	qup_i2c6_clk: qup_i2c6_clk-state {
		pins = "gpio19";
		function = "qup0_se6_l1";
	};

	qup_i2c6_data: qup_i2c6_data-state {
		pins = "gpio18";
		function = "qup0_se6_l0";
	};

	qup_i2c6_sleep: qup_i2c6_sleep-state {
		pins = "gpio18", "gpio19";
		function = "gpio";
	};

	qup_i2c7_clk: qup_i2c7_clk-state {
		pins = "gpio21";
		function = "qup0_se7_l1";
	};

	qup_i2c7_data: qup_i2c7_data-state {
		pins = "gpio20";
		function = "qup0_se7_l0";
	};

	qup_i2c7_sleep: qup_i2c7_sleep-state {
		pins = "gpio20", "gpio21";
		function = "gpio";
	};

	qup_i2c8_clk: qup_i2c8_clk-state {
		pins = "gpio23";
		function = "qup0_se8_l1";
	};

	qup_i2c8_data: qup_i2c8_data-state {
		pins = "gpio22";
		function = "qup0_se8_l0";
	};

	qup_i2c8_sleep: qup_i2c8_sleep-state {
		pins = "gpio22", "gpio23";
		function = "gpio";
	};

	qup_i2c9_clk: qup_i2c9_clk-state {
		pins = "gpio26";
		function = "qup0_se9_l1";
	};

	qup_i2c9_data: qup_i2c9_data-state {
		pins = "gpio27";
		function = "qup0_se9_l0";
	};

	qup_i2c9_sleep: qup_i2c9_sleep-state {
		pins = "gpio27", "gpio26";
		function = "gpio";
	};

	qup_spi0_clk: qup_spi0_clk-state {
		pins = "gpio0";
		function = "qup0_se0_l2";
	};

	qup_spi0_cs: qup_spi0_cs-state {
		pins = "gpio1";
		function = "qup0_se0_l3";
	};

	qup_spi0_miso: qup_spi0_miso-state {
		pins = "gpio2";
		function = "qup0_se0_l0";
	};

	qup_spi0_mosi: qup_spi0_mosi-state {
		pins = "gpio3";
		function = "qup0_se0_l1";
	};

	qup_spi0_sleep: qup_spi0_sleep-state {
		pins = "gpio0", "gpio1", "gpio2", "gpio3";
		function = "gpio";
	};

	qup_spi2_clk: qup_spi2_clk-state {
		pins = "gpio8";
		function = "qup0_se2_l2";
	};

	qup_spi2_cs: qup_spi2_cs-state {
		pins = "gpio9";
		function = "qup0_se2_l3";
	};

	qup_spi2_miso: qup_spi2_miso-state {
		pins = "gpio6";
		function = "qup0_se2_l0";
	};

	qup_spi2_mosi: qup_spi2_mosi-state {
		pins = "gpio7";
		function = "qup0_se2_l1";
	};

	qup_spi2_sleep: qup_spi2_sleep-state {
		pins = "gpio6", "gpio7", "gpio8", "gpio9";
		function = "gpio";
	};

	qup_spi5_clk: qup_spi5_clk-state {
		pins = "gpio16";
		function = "qup0_se5_l2";
	};

	qup_spi5_cs: qup_spi5_cs-state {
		pins = "gpio17";
		function = "qup0_se5_l3";
	};

	qup_spi5_miso: qup_spi5_miso-state {
		pins = "gpio14";
		function = "qup0_se5_l0";
	};

	qup_spi5_mosi: qup_spi5_mosi-state {
		pins = "gpio15";
		function = "qup0_se5_l1";
	};

	qup_spi5_sleep: qup_spi5_sleep-state {
		pins = "gpio14", "gpio15", "gpio16", "gpio17";
		function = "gpio";
	};

	qup_spi6_clk: qup_spi6_clk-state {
		pins = "gpio28";
		function = "qup0_se6_l2";
	};

	qup_spi6_cs: qup_spi6_cs-state {
		pins = "gpio29";
		function = "qup0_se6_l3";
	};

	qup_spi6_miso: qup_spi6_miso-state {
		pins = "gpio18";
		function = "qup0_se6_l0";
	};

	qup_spi6_mosi: qup_spi6_mosi-state {
		pins = "gpio19";
		function = "qup0_se6_l1";
	};

	qup_spi6_sleep: qup_spi6_sleep-state {
		pins = "gpio18", "gpio19", "gpio28", "gpio29";
		function = "gpio";
	};

	qup_spi8_clk: qup_spi8_clk-state {
		pins = "gpio24";
		function = "qup0_se8_l2";
	};

	qup_spi8_cs: qup_spi8_cs-state {
		pins = "gpio25";
		function = "qup0_se8_l3";
	};

	qup_spi8_miso: qup_spi8_miso-state {
		pins = "gpio22";
		function = "qup0_se8_l0";
	};

	qup_spi8_mosi: qup_spi8_mosi-state {
		pins = "gpio23";
		function = "qup0_se8_l1";
	};

	qup_spi8_sleep: qup_spi8_sleep-state {
		pins = "gpio22", "gpio23", "gpio24", "gpio25";
		function = "gpio";
	};

	qup_spi9_clk: qup_spi9_clk-state {
		pins = "gpio50";
		function = "qup0_se9_l2";
	};

	qup_spi9_cs: qup_spi9_cs-state {
		pins = "gpio51";
		function = "qup0_se9_l3";
	};

	qup_spi9_miso: qup_spi9_miso-state {
		pins = "gpio48";
		function = "qup0_se9_l0";
	};

	qup_spi9_mosi: qup_spi9_mosi-state {
		pins = "gpio49";
		function = "qup0_se9_l1";
	};

	qup_spi9_sleep: qup_spi9_sleep-state {
		pins = "gpio48", "gpio49", "gpio50", "gpio51";
		function = "gpio";
	};

	qup_uart0_rx: qup-uart0-rx-state {
		pins = "gpio1";
		function = "qup0_se0_l3";
	};

	qup_uart0_sleep: qup-uart0-sleep-state {
		pins = "gpio0", "gpio1";
		function = "gpio";
	};

	qup_uart0_tx: qup-uart0-tx-state {
		pins = "gpio0";
		function = "qup0_se0_l2";
	};

	qup_uart1_rx: qup-uart1-rx-state {
		pins = "gpio5";
		function = "qup0_se1_l3";
	};

	qup_uart1_sleep: qup-uart1-sleep-state {
		pins = "gpio4", "gpio5";
		function = "gpio";
	};

	qup_uart1_tx: qup-uart1-tx-state {
		pins = "gpio4";
		function = "qup0_se1_l2";
	};

	qup_uart2_cts: qup-uart2-cts-state {
		pins = "gpio6";
		function = "qup0_se2_l0";
	};

	qup_uart2_default: qup-uart2-default-state {
		pins = "gpio8", "gpio9", "gpio6", "gpio7";
		function = "gpio";
	};

	qup_uart2_rts: qup-uart2-rts-state {
		pins = "gpio7";
		function = "qup0_se2_l1";
	};

	qup_uart2_rx: qup-uart2-rx-state {
		pins = "gpio9";
		function = "qup0_se2_l3";
	};

	qup_uart2_sleep: qup-uart2-sleep-state {
		pins = "gpio9";
		function = "gpio";
	};

	qup_uart2_tx: qup-uart2-tx-state {
		pins = "gpio8";
		function = "qup0_se2_l2";
	};

	qup_uart3_rx: qup-uart3-rx-state {
		pins = "gpio10";
		function = "qup0_se3_l3";
	};

	qup_uart3_sleep: qup-uart3-sleep-state {
		pins = "gpio10", "gpio11";
		function = "gpio";
	};

	qup_uart3_tx: qup-uart3-tx-state {
		pins = "gpio11";
		function = "qup0_se3_l2";
	};

	qup_uart4_rx: qup-uart4-rx-state {
		pins = "gpio12";
		function = "qup0_se4_l3";
	};

	qup_uart4_sleep: qup-uart4-sleep-state {
		pins = "gpio12", "gpio13";
		function = "gpio";
	};

	qup_uart4_tx: qup-uart4-tx-state {
		pins = "gpio13";
		function = "qup0_se4_l2";
	};

	qup_uart5_cts: qup-uart5-cts-state {
		pins = "gpio14";
		function = "qup0_se5_l0";
	};

	qup_uart5_default: qup-uart5-default-state {
		pins = "gpio16", "gpio17", "gpio14", "gpio15";
		function = "gpio";
	};

	qup_uart5_rts: qup-uart5-rts-state {
		pins = "gpio15";
		function = "qup0_se5_l1";
	};

	qup_uart5_rx: qup-uart5-rx-state {
		pins = "gpio17";
		function = "qup0_se5_l3";
	};

	qup_uart5_sleep: qup-uart5-sleep-state {
		pins = "gpio17";
		function = "gpio";
	};

	qup_uart5_tx: qup-uart5-tx-state {
		pins = "gpio16";
		function = "qup0_se5_l2";
	};

	qup_uart6_cts: qup-uart6-cts-state {
		pins = "gpio18";
		function = "qup0_se6_l0";
	};

	qup_uart6_default: qup-uart6-default-state {
		pins = "gpio28", "gpio29", "gpio18", "gpio19";
		function = "gpio";
	};

	qup_uart6_rts: qup-uart6-rts-state {
		pins = "gpio19";
		function = "qup0_se6_l1";
	};

	qup_uart6_rx: qup-uart6-rx-state {
		pins = "gpio29";
		function = "qup0_se6_l3";
	};

	qup_uart6_sleep: qup-uart6-sleep-state {
		pins = "gpio29";
		function = "gpio";
	};

	qup_uart6_tx: qup-uart6-tx-state {
		pins = "gpio28";
		function = "qup0_se6_l2";
	};

	qup_uart7_rx: qup-uart7-rx-state {
		pins = "gpio20";
		function = "qup0_se7_l3";
	};

	qup_uart7_sleep: qup-uart7-sleep-state {
		pins = "gpio20", "gpio21";
		function = "gpio";
	};

	qup_uart7_tx: qup-uart7-tx-state {
		pins = "gpio21";
		function = "qup0_se7_l2";
	};

	qup_uart8_cts: qup_uart8_cts-state {
		pins = "gpio22";
		function = "qup0_se8_l0";
	};

	qup_uart8_default_ctsrtsrx: qup_uart8_default_ctsrtsrx-state {
		pins = "gpio22", "gpio23", "gpio25";
		function = "gpio";
	};

	qup_uart8_default_tx: qup_uart8_default_tx-state {
		pins = "gpio24";
		function = "gpio";
	};

	qup_uart8_rts: qup_uart8_rts-state {
		pins = "gpio23";
		function = "qup0_se8_l1";
	};

	qup_uart8_rx_wake: qup_uart8_rx_wake-state {
		pins = "gpio25";
		function = "gpio";
	};

	qup_uart8_rx_active: qup_uart8_rx_active-state {
		pins = "gpio25";
		function = "qup0_se8_l3";
	};

	qup_uart8_sleep: qup_uart8_sleep-state {
		pins = "gpio25";
		function = "gpio";
	};

	qup_uart8_tx: qup_uart8_tx-state {
		pins = "gpio24";
		function = "qup0_se8_l2";
	};

	qup_uart9_rx: qup-uart9-rx-state {
		pins = "gpio27";
		function = "qup0_se9_l3";
	};

	qup_uart9_sleep: qup-uart9-sleep-state {
		pins = "gpio26", "gpio27";
		function = "gpio";
	};

	qup_uart9_tx: qup-uart9-tx-state {
		pins = "gpio26";
		function = "qup0_se9_l2";
	};

};


&soc {
	touch_panel_extavdd: touch_gpio_regulator@1 {
		compatible = "qti-regulator-fixed";
		regulator-name = "touch_panel_extavdd";
		regulator-min-microvolt = <3300000>;
		regulator-max-microvolt = <3300000>;
		regulator-enable-ramp-delay = <233>;
		gpio = <&tlmm 63 0>;
		enable-active-high;
		regulator-boot-on;
		proxy-supply = <&touch_panel_extavdd>;
		qcom,proxy-consumer-enable;
		pinctrl-names = "default";
		pinctrl-0 = <&touch_panel_extavdd_default>;
	};
};

&i2c4 {
	status = "ok";
	gt9xx-i2c@5d {
		compatible = "goodix,gt928";
		reg = <0x5d>;
		status = "okay";
		interrupt-parent = <&tlmm>;
		interrupts = <85 0x2800>;

		reset-gpios = <&tlmm 76 0x1>;
		irq-gpios = <&tlmm 85 0x1>;
		irq-flags = <2>;
		vdd_ana-supply = <&touch_panel_extavdd>;

		touchscreen-max-id = <11>;
		touchscreen-size-x = <1080>;
		touchscreen-size-y = <1920>;
		touchscreen-max-w = <1024>;
		touchscreen-max-p = <1024>;
		/*touchscreen-key-map = <172>, <158>;*/ /*KEY_HOMEPAGE, KEY_BACK*/

		goodix,type-a-report = <0>;
		goodix,driver-send-cfg = <1>;
		goodix,create-wr-node = <1>;
		goodix,wakeup-with-reset = <0>;
		goodix,resume-in-workqueue = <0>;
		goodix,int-sync = <1>;
		goodix,swap-x2y = <0>;
		goodix,esd-protect = <1>;
		goodix,pen-suppress-finger = <0>;
		goodix,auto-update = <0>;
		goodix,auto-update-cfg = <0>;
		goodix,power-off-sleep = <0>;

		goodix,cfg-group0 = [
			42 38 04 80 07 0A 35 00 01 08 32 05 50 3C 03 05 00 00 00 00 00 00 00 18 1A 1E 14 8C 2E 0E
			32 34 7F 08 00 00 01 BB 02 1D 00 00 00 00 00 03 64 32 00 00 00 23 46 94 C5 02 00 00 00 00
			A7 25 00 92 2B 00 82 31 00 74 38 00 66 41 00 66 00 00 00 00 00 00 00 00 00 00 00 00 00 00
			00 00 00 00 00 00 00 00 00 00 00 00 00 00 00 00 00 00 00 00 00 00 1C 1A 18 16 14 12 10 0E
			0C 0A 08 06 04 02 00 00 00 00 00 00 00 00 00 00 00 00 00 00 00 00 00 02 04 06 08 0A 0C 0F
			10 12 13 14 16 2A 29 28 26 24 22 21 20 1F 1E 1D 1C 18 00 00 00 00 00 00 00 00 00 00 00 00
			00 00 00 00 82 01];

		goodix,qts_en;
		goodix,touch-type = "primary";
		qts,trusted-touch-mode = "vm_mode";
		qts,touch-environment = "pvm";
		qts,trusted-touch-type = "primary";
		qts,trusted-touch-spi-irq = <267>;
		qts,trusted-touch-io-bases = <0x4a90000>;
		qts,trusted-touch-io-sizes = <0x1000>;
		qts,trusted-touch-vm-gpio-list = <&tlmm 12 0 &tlmm 13 0 &tlmm 76 0 &tlmm 85 0x2008>;
	};
};
